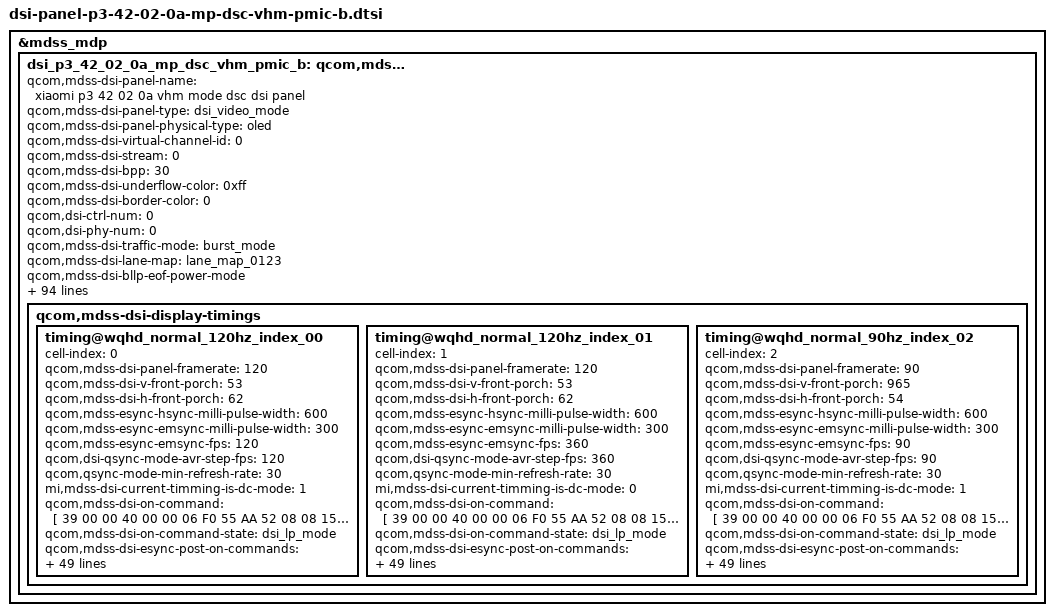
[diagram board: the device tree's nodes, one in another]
&mdss_mdp {
	dsi_p3_42_02_0a_mp_dsc_vhm_pmic_b: qcom,mdss_dsi_p3_42_02_0a_mp_dsc_vhm_pmic_b {
		qcom,mdss-dsi-panel-name = "xiaomi p3 42 02 0a vhm mode dsc dsi panel";
		qcom,mdss-dsi-panel-type = "dsi_video_mode";
		qcom,mdss-dsi-panel-physical-type = "oled";
		qcom,mdss-dsi-virtual-channel-id = <0>;
		qcom,mdss-dsi-stream = <0>;
		qcom,mdss-dsi-bpp = <30>;

		qcom,mdss-dsi-underflow-color = <0xff>;
		qcom,mdss-dsi-border-color = <0>;
		qcom,dsi-ctrl-num = <0>;
		qcom,dsi-phy-num = <0>;
		qcom,mdss-dsi-traffic-mode = "burst_mode";
		qcom,mdss-dsi-lane-map = "lane_map_0123";
		qcom,mdss-dsi-bllp-eof-power-mode;
		qcom,mdss-dsi-bllp-power-mode;
		qcom,mdss-dsi-lane-0-state;
		qcom,mdss-dsi-lane-1-state;
		qcom,mdss-dsi-lane-2-state;
		qcom,mdss-dsi-lane-3-state;
		qcom,mdss-dsi-color-order = "rgb_swap_rgb";
		qcom,mdss-dsi-dma-trigger = "trigger_sw";
		qcom,mdss-dsi-mdp-trigger = "none";
		qcom,mdss-dsi-reset-sequence =<1 1>, <0 1>, <1 10>;
		qcom,mdss-pan-physical-width-dimension = <673>;
		qcom,mdss-pan-physical-height-dimension = <1466>;
		qcom,mdss-dsi-te-pin-select = <1>;
		qcom,mdss-dsi-wr-mem-start = <0x2c>;
		qcom,mdss-dsi-wr-mem-continue = <0x3c>;
		//qcom,mdss-dsi-te-dcs-command = <1>;
		//qcom,mdss-dsi-te-check-enable;
		//qcom,mdss-dsi-te-using-te-pin;
		qcom,mdss-dsi-tx-eot-append;
		qcom,mdss-dsi-lp11-init;
		qcom,mdss-dsi-bl-inverted-dbv;
		qcom,mdss-dsi-panel-dimming-enabled;
		qcom,bl-update-flag = "delay_until_first_frame";
		qcom,mdss-dsi-panel-hdr-enabled;
		qcom,mdss-dsi-panel-hdr-color-primaries = <14500 15500 32000
			17000 15500 30000 8000 3000>;
		qcom,mdss-dsi-panel-peak-brightness = <32000000>;
		qcom,mdss-dsi-panel-blackness-level = <3230>;
		//qcom,mdss-dsi-dma-schedule-line = <1>;
		//qcom,mdss-dsi-dma-schedule-window = <50>;
		qcom,spr-pack-type = "pentile";
		/*
		 * ###############################################################
		 * # Pentile SPR phases for SM8850 and later
		 * ###############################################################
		 * # RG/BG Type A    BG/RG Type A    GR/GB Type A    GB/GR Type A
		 * # R B R B ...     B R B R ...      R B R B ...     B R B R ...
		 * #  G G G G ...     G G G G ...    G G G G ...     G G G G ...
		 * #
		 * # RG/BG Type B    BG/RG Type B    GR/GB Type B    GB/GR Type B
		 * #  G G G G ...     G G G G ...    G G G G ...     G G G G ...
		 * # R B R B ...     B R B R ...      R B R B ...     B R B R ...
		 * ###############################################################
		 */
		qcom,spr-pentile-pack-type = "BG-RG Type A";

		qcom,mdss-disable-cesta-hw-sleep;

		qcom,mdss-dsi-display-timings {

			timing@wqhd_normal_120hz_index_00 {
				#include "dsi-panel-p3-42-02-0a-mp-dsc-vhm-pmic-b-common.dtsi"

				cell-index = <0>;
				qcom,mdss-dsi-panel-framerate = <120>;
				qcom,mdss-dsi-v-front-porch = <53>;
				qcom,mdss-dsi-h-front-porch = <62>;

				qcom,mdss-esync-hsync-milli-pulse-width = <600>;
				qcom,mdss-esync-emsync-milli-pulse-width = <300>;
				qcom,mdss-esync-emsync-fps = <120>;
				qcom,dsi-qsync-mode-avr-step-fps = <120>;
				qcom,qsync-mode-min-refresh-rate = <30>;

				mi,mdss-dsi-current-timming-is-dc-mode = <1>;

				qcom,mdss-dsi-on-command = [
					// LCTC ON
					39 00 00 40 00 00 06 F0 55 AA 52 08 08
					15 00 00 40 00 00 02 BF 21
					// ACTC ON
					15 00 00 40 00 00 02 6F B7
					15 00 00 00 00 00 02 BF 11
					// Power Domain
					39 00 00 40 00 00 06 F0 55 AA 52 08 01
					15 00 00 40 00 00 02 6F 49
					39 00 00 00 00 00 06 B9 01 22 00 EE EE
					// AOD pump
					39 00 00 40 00 00 06 F0 55 AA 52 08 01
					39 00 00 00 00 00 05 B2 00 00 FF 03
					// Data chopper setting
					39 00 00 40 00 00 06 F0 55 AA 52 08 01
					15 00 00 40 00 00 02 6F 23
					39 00 00 00 00 00 04 D9 CB 49 13
					// EM TH2 Duty Setting
					39 00 00 40 00 00 06 F0 55 AA 52 08 00
					39 00 00 40 00 00 02 6F 21
					39 00 00 40 00 00 09 B2 00 28 00 28 00 3C 00 28
					39 00 00 40 00 00 02 6F 75
					39 00 00 40 00 00 09 B2 00 28 00 28 00 3C 00 28
					39 00 00 40 00 00 02 6F 71
					39 00 00 00 00 00 03 B2 00 28
					// PMIC Fast discharge
 					39 00 00 40 00 00 02 6F 51
 					39 00 00 40 00 00 02 D5 02
 					39 00 00 40 00 00 02 6F 54
 					39 00 00 00 00 00 02 D5 1F
 					// Switch VGMP by Fcon
 					39 00 00 40 00 00 06 F0 55 AA 52 08 01
 					39 00 00 40 00 00 02 6F 16
 					39 00 00 00 00 00 05 C6 87 22 2C 2C
 					// demura,FLASH CODE
					39 00 00 40 00 00 06 F0 55 AA 52 08 00
					39 00 00 40 00 00 02 C7 44
					39 00 00 40 00 00 02 6F 31
					39 00 00 40 00 00 03 C0 00 20
					39 00 00 40 00 00 02 6F 06
					39 00 00 40 00 00 03 C7 60 60
					39 00 00 40 00 00 02 6F 08
					39 00 00 40 00 00 03 C7 66 26
					39 00 00 40 00 00 06 F0 55 AA 52 08 04
					39 00 00 00 00 00 02 C0 20
 					// SVM
 					39 00 00 40 00 00 06 F0 55 AA 52 08 00
 					39 00 00 40 00 00 02 6F 20
 					39 00 00 40 00 00 02 B2 03
 					39 00 00 40 00 00 06 F0 55 AA 52 08 01
 					39 00 00 40 00 00 02 6F F0
 					39 00 00 40 00 00 02 C0 F1
 					39 00 00 40 00 00 02 6F F1
 					39 00 00 40 00 00 03 C0 12 12
 					39 00 00 40 00 00 02 6F F4
  					39 00 00 40 00 00 03 C0 12 12
  					39 00 00 40 00 00 02 6F 01
  					39 00 00 40 00 00 04 CE 00 00 00
  					39 00 00 40 00 00 02 6F 94
  					39 00 00 40 00 00 04 E2 00 11 00
  					39 00 00 40 00 00 02 6F 24
  					39 00 00 40 00 00 13 E5 42 8C 94 90 92 07 42 8C 94 90 92 07 42 8C 94 90 92 07
  					39 00 00 40 00 00 02 6F A7
  					39 00 00 40 00 00 02 E7 C0
  					39 00 00 40 00 00 02 6F DA
 					39 00 00 40 00 00 03 E7 00 00
 					39 00 00 40 00 00 06 F0 55 AA 52 08 01
 					39 00 00 40 00 00 02 6F E3
 					39 00 00 00 00 00 18 E5 FF FF FF FF 9B 9B 61 61 4D 4D 3A 3A 00 00 00 00 00 00 00 00 00 00 00
 					// APL,Normal 32,HBM 8,APL 0
 					39 00 00 40 00 00 06 F0 55 AA 52 08 00
 					39 00 00 40 00 00 02 6F 78
 					39 00 00 40 00 00 18 B0 11 00 2A 00 C2 01 DA 03 7C 05 B1 08 80 0B EE 0F FF 05 55 05 56 05 55
 					39 00 00 40 00 00 02 6F 6F
 					39 00 00 40 00 00 07 B0 02 62 04 C4 02 62
 					39 00 00 40 00 00 06 F0 55 AA 52 08 08
 					39 00 00 40 00 00 17 C1 9C FF CC FF FF CC FF FF CC FF FF DC FF FF DD FF FF FF 7F FF 0E FF
 					39 00 00 40 00 00 02 6F 1D
 					39 00 00 40 00 00 07 C1 00 FF FF 4F 00 FF
 					39 00 00 40 00 00 02 6F 23
 					39 00 00 40 00 00 15 C1 0C FF CC FF FF CC FF FF CC FF FF DC FF FF DD FF FF CF 7F 67
 					39 00 00 40 00 00 02 6F 37
 					39 00 00 40 00 00 15 C1 0C FF CC FF FF CC FF FF CC FF FF DC FF FF DD FF FF FF 7F FF
 					39 00 00 40 00 00 02 6F 4B
 					39 00 00 00 00 00 15 C1 0C FF CC FF FF CC FF FF CC FF FF DC FF FF DD FF FF CF 7F 67
  					// Data Scaling DBV_TH
  					39 00 00 00 00 00 2D BA 00 07 00 26 00 26 00 64 00 64 00 AC 00 AC 01 26 01 26 02 5F 02 5F 02 60 02 60 07 FB 07 FB 17 FE 17 FE 1F FF 1F FF 34 BC 34 BC 3F FE
					// ESD ERR Flag
					39 00 00 40 00 00 06 F0 55 AA 52 08 00
					39 00 00 40 00 00 03 BE 47 45
					15 00 00 40 00 00 02 6F 05
					15 00 00 40 00 00 02 BE 00
					15 00 00 40 00 00 02 6F 19
					39 00 00 00 00 00 05 BE 10 0A 00 9C
					// DVDD Low Voltage detect
					39 00 00 40 00 00 06 F0 55 AA 52 08 01
					15 00 00 40 00 00 02 6F 03
					15 00 00 00 00 00 02 C7 C7
  					// ESD protect
  					39 00 00 40 00 00 05 FF AA 55 A5 81
  					39 00 00 40 00 00 02 6F 0F
  					39 00 00 00 00 00 02 FD 80
  					// 1220*2656
  					39 00 00 40 00 00 05 2A 00 00 04 C3
  					39 00 00 00 00 00 05 2B 00 00 0A 5F
  					// VESA Setting
 					39 00 00 40 00 00 02 90 03
 					39 00 00 40 00 00 02 6F 01
 					39 00 00 40 00 00 02 90 43
 					39 00 00 40 00 00 13 91 89 28 00 10 C2 00 02 32 01 9C 00 08 06 67 05 92 10 E0
 					// DC 120Hz
 					39 00 00 40 00 00 02 2F 30
 					39 00 00 00 00 00 02 6D 00
 					// TE On
 					39 00 00 00 00 00 02 35 00
 					// DBV = 0
					39 00 00 00 00 00 03 51 00 00
					// idle_dimming_dbv = 0
					39 00 00 40 00 00 02 6F 04
					39 00 00 00 00 00 03 51 00 00
					// BCTRL = 1, DD = 0
					39 00 00 00 00 00 02 53 20
					// 0x00 Data remap off 0x0F Data remap on
					39 00 00 40 00 00 06 F0 55 AA 52 08 00
					39 00 00 40 00 00 02 6F 02
					39 00 00 40 00 00 02 B2 0F
 					// Skip mode setting
					39 00 00 40 00 00 04 8C 00 00 10
					39 00 00 40 00 00 03 5A 00 00
					39 00 00 00 00 00 02 2F 30
					// AP SPR
					39 00 00 40 00 00 06 F0 55 AA 52 08 03
					39 00 00 40 00 00 02 6F 09
					39 00 00 40 00 00 07 DE 10 34 25 30 14 25
					39 00 00 40 00 00 06 F0 55 AA 52 08 07
					39 00 00 40 00 00 06 B0 84 44 00 00 40
					39 00 00 40 00 00 07 B1 18 08 00 08 18 00
					39 00 00 00 00 00 13 91 AB F0 00 10 C1 00 01 CB 00 73 00 33 06 67 1F B0 11 40
					// Still = 0 VDO no RAM
					39 00 00 00 00 00 02 18 00
					// GPO2 = Vsync
					39 00 00 40 00 00 06 F0 55 AA 52 08 00
					39 00 00 40 00 00 02 6F 02
 					39 00 00 40 00 00 03 BE 4F 4A
 					39 00 00 40 00 00 02 6F 0A
 					39 00 00 00 00 00 02 BE 02
 					// VDO with RAM
 					39 00 00 40 00 00 06 F0 55 AA 52 08 01
 					39 00 00 40 00 00 02 6F 17
 					39 00 00 00 00 00 02 B8 07
 					// GMA By Frame
 					39 00 00 40 00 00 06 F0 55 AA 52 08 02
 					39 00 00 00 00 00 02 CC 10
					// Idle Mode porch
					39 00 00 40 00 00 05 FF AA 55 A5 81
					39 00 00 40 00 00 02 6F 0F
					39 00 00 00 00 00 02 F5 0E
					// Demura on
					39 00 00 40 00 00 06 F0 55 AA 52 08 04
					39 00 00 00 00 00 02 CA 01
					// A3 Setting
					39 00 00 40 00 00 06 F0 55 AA 52 08 04
					39 00 00 40 00 00 02 6F 06
					39 00 00 40 00 00 02 B5 00
					39 00 00 40 00 00 05 FF AA 55 A5 81
					39 00 00 40 00 00 02 6F 0D
					39 00 00 40 00 00 02 FD 40
					39 00 00 40 00 00 07 51 00 00 00 00 00 00
					39 00 00 00 00 00 06 A3 84 02 5F 02 5F
					// osc trace
					39 00 00 40 00 00 06 F0 55 AA 52 08 01
					39 00 00 40 00 00 37 C3 00 00 00 00 EA 00 00 00 00 EA 00 00 00 00 00 00 00 00 00 00 00 00 00 00 00 00 00 00 00 00 00 00 00 00 00 00 00 00 00 00 00 00 00 00 00 00 00 11 00 AA 02 AA 02 00
					39 00 00 00 00 00 24 EA 11 02 3C 00 0D 0B 0A 01 7C 00 00 11 02 3C 00 0D 0B 0A 01 A7 00 00 00 00 00 00 01 7C 01 A7 00 0C 00 00 40
					//vdo drop=1.1s
					39 00 00 40 00 00 06 F0 55 AA 52 08 03
					15 00 00 40 00 00 02 6F 1D
					15 00 00 40 00 00 02 C6 0C
					//0xB4AA=4583  46250*8*3=1.1S
					15 00 00 40 00 00 02 6F 2C
					39 00 00 00 00 00 07 C6 AA B4 AA B4 AA B4
					// Sleep Out
					05 00 00 00 78 00 01 11
					// expand demura lut 16DBV*7Gray
					39 00 00 40 00 00 13 A3 84 02 5F 02 5F 02 04 B5 02 03 00 03 00 00 00 00 00 00
					39 00 00 40 00 00 02 6F 12
					39 00 00 40 00 00 0E A3 01 00 9D 00 00 AA 00 00 00 00 00 00 00
					39 00 00 40 00 00 02 6F 53
					39 00 00 40 00 00 0E A3 02 04 B5 02 03 00 0C 00 00 00 00 00 00
					39 00 00 40 00 00 02 6F 60
					39 00 00 00 00 00 0E A3 01 00 9D 00 00 AA 00 00 00 00 00 00 00

					// Display On
					05 00 00 00 00 00 01 29
					// ESD ERR Flag on
					39 00 00 40 00 00 06 F0 55 AA 52 08 00
					15 00 00 40 00 00 02 6F 05
					15 00 00 00 00 00 02 BE 08

					// VHM Setting
					// opt_level2_te_fall=1,Level TE drop position reference multi-TE
					39 01 00 40 00 00 04 8D 00 20 00
					15 01 00 40 00 00 02 6F 8A
					15 01 00 40 00 00 02 44 19
					39 01 00 40 00 00 06 F0 55 AA 52 08 00
					39 01 00 40 00 00 03 BE 47 45
					// Level_TE(0x6A)、ARP(0x77)、Test_TE(0x7D)
					15 01 00 40 00 00 02 6F 14
					39 01 00 40 00 00 04 35 6A 77 E0
					15 01 00 40 00 00 02 6F 17
					39 01 00 40 00 00 04 35 6A 77 E0
					15 01 00 40 00 00 02 6F 1A
					39 01 00 40 00 00 04 35 6A 77 E0
					15 01 00 40 00 00 02 6F 1D
					39 01 00 40 00 00 04 35 6A 77 E0
					// dyn_multi_te_start[13:0]adjust TE left
					15 01 00 40 00 00 02 6F 26
					39 01 00 40 00 00 03 44 00 78
					// dyn_multi_te_start_skip[13:0]adjust TE left
					15 01 00 40 00 00 02 6F 28
					39 01 00 40 00 00 03 44 00 78
					// dyn_multi_te_start_video[13:0]adjust TE left
					15 01 00 40 00 00 02 6F 42
					39 01 00 40 00 00 03 44 00 78
					// dyn_multi_te_start_vdo_skip[13:0]adjust TE left
					15 01 00 40 00 00 02 6F 64
					39 01 00 40 00 00 03 44 00 78
					// dyn_multi_te_width[7:0]
					15 01 00 40 00 00 02 6F 2A
					15 01 00 40 00 00 02 44 1A
					// dyn_multi_te_interval[13:0]=2736
					15 01 00 40 00 00 02 6F 2B
					39 01 00 40 00 00 03 44 0A B0
					// TE07_DPU_DELAY[7:0]
					15 01 00 40 00 00 02 6F 02
					15 01 00 40 00 00 02 35 18
					// SEL_ECK_CYCLE_LINE=0,EXTEND_VFP_LINE_ECLK_EN=0
					39 01 00 40 00 00 06 F0 55 AA 52 08 00
					15 01 00 40 00 00 02 6F 04
					15 01 00 40 00 00 02 BA 00
					// TE07_DPU_DELAY_VDO[7:0]
					15 01 00 40 00 00 02 6F 0C
					15 01 00 40 00 00 02 35 00
					// set_dsi_mode=1
					15 01 00 40 00 00 02 71 01
					// still=1
					15 01 00 40 00 00 02 18 00
					// REGW 0x6D,0x04
					// EXT_HSYNC_EN=1
					39 01 00 40 00 00 06 F0 55 AA 52 08 03
					15 01 00 40 00 00 02 6F 06
					15 01 00 40 00 00 02 BA 01
					// DFC_mode3
					39 01 00 40 00 00 04 2F 30 05 30
					// ARP_TE selects TE1F
					39 01 00 40 00 00 06 F0 55 AA 52 08 00
					15 01 00 40 00 00 02 6F 35
					15 01 00 40 00 00 02 B1 10
					39 01 00 40 00 00 06 F0 55 AA 52 08 00
					// opt_dis_vdo_ltpo_crc=1(Disable CRC calculation), 0 (default: calculate CRC)
					15 01 00 40 00 00 02 6F DD
					15 01 00 40 00 00 02 BA 80
					// FD fixedly retreats one line
					39 01 00 40 00 00 06 F0 55 AA 52 08 08
					15 01 00 40 00 00 02 6F 02
					15 01 00 40 00 00 02 E0 81
					// 20250514
					// opt_v2c_chg_reload_fskip=1:Set skip frame_skip to return EM to sequence 1 without skipping the sequence
					// opt_v2c_chg_reload_fskip=0:Jump out of sequence
					// opt_level2_te_fall=1(707A only) _wrote about deletion before
					// REGW 0x6F,0x8A
					// REGW 0x44,0x11
					// 20BAE2[3]=1，V2C receives the outbound VSS and requests sequence 1 back (this question assumes that the V2C VSS follows the TE and does not generate an ARP, which would allow the VSS to match the TE's response)
					39 01 00 40 00 00 06 F0 55 AA 52 08 00
					15 01 00 40 00 00 02 6F E2
					15 01 00 40 00 00 02 BA 08
					// 31FB00[4]=1，By default, the frame sent to V2C will not use extd_vfp. When vcnt_val_clr is seen, v is generated. Setting opt_rgb_v_gate_afp=1 will make the V2C frame also use extd_vfp
					39 01 00 40 00 00 05 FF AA 55 A5 81
					15 01 00 40 00 00 02 6F 00
					15 01 00 40 00 00 02 FB 10
					// CMD3,Page1
					// Enable the VESA CLK function to stop CLK in the skip frame. VESA CLK will still be enabled by MIPI writing
					39 01 00 40 00 00 05 FF AA 55 A5 81
					15 01 00 40 00 00 02 6F 1C
					15 01 00 40 00 00 02 FB 10
					// 707A_P3_Y=2736，Xiaomi P3_VHM, still=1, using TE2 to achieve ALS 60Hz
					// TE_RW_rising_command mode
					// dyn_multi_te_start=dyn_multi_te_start_skip=0x1A/ =dyn_multi_te_width=0x1A/dyn_multi_te_interval=0x1560
					15 01 00 40 00 00 02 6F 2D
					39 01 00 40 00 00 08 44 00 1A 00 1A 1A 15 60
					// dyn_multi_te_start=dyn_multi_te_start_skip=0x1A/ =dyn_multi_te_width=0x1A/dyn_multi_te_interval=0x1560
					15 01 00 40 00 00 02 6F 3B
					39 01 00 40 00 00 08 44 00 1A 00 1A 1A 15 60
					// 707A
					15 01 00 40 00 00 02 6F 69
					15 01 00 00 00 00 02 44 02
					// TE20_sel_cmd=7D(Test TE)
					// REGW 0x6F,0x16
					// REGW 0x35,0xE0
					// REGW 0x6F,0x19
					// REGW 0x35,0xE0
					// REGW 0x6F,0x1C
					// REGW 0x35,0xE0
					// REGW 0x6F,0x1F
					// REGW 0x35,0xE0
					//VHM setting,DC write common after 6D
					//DC
					15 01 00 40 00 00 02 6F 2B
					39 01 00 40 00 00 03 44 0A B0
					//DC 1HZ
					39 01 00 40 00 00 06 F0 55 AA 52 08 00
					15 01 00 40 00 00 02 6F 0E
					15 01 00 40 00 00 02 C0 00
					15 01 00 40 00 00 02 6F DE
					15 01 00 40 00 00 02 BA 00
					15 01 00 40 00 00 02 6F 04
					15 01 00 40 00 00 02 35 01
					15 01 00 40 00 00 02 6F 14
					15 01 00 40 00 00 02 35 6A
					39 01 00 40 00 00 03 44 0A 60
					15 01 00 40 00 00 02 8C 02
					15 01 00 40 00 00 02 6D 0B
					//VHM setting,DC write common after 6D
					//120Hz DC Skip Frame Rate
					39 01 00 40 00 00 06 F0 55 AA 52 08 00
					15 01 00 40 00 00 02 6F B8
					39 01 00 40 00 00 09 BA 10 10 00 00 00 01 20 21
					15 01 00 40 00 00 02 6F C0
					39 01 00 40 00 00 09 BA 10 10 00 00 00 01 20 21
					15 01 00 40 00 00 02 6F 5A
					39 01 00 40 00 00 09 D1 10 10 00 00 00 01 20 21
					15 01 00 40 00 00 02 6F 31
					15 01 00 40 00 00 02 C0 00
					39 01 00 40 00 00 2C A9 01 00 2F 00 00 30 02 01 B9 2C 2C 21 02 01 B9 30 30 F0 01 00 A2 00 14 05 02 01 B9 2C 2C 22 00 00 00 00 00 00 00 02 01 B9 30 30 26
					39 01 00 40 00 00 13 A3 84 02 5F 02 5F 02 04 B5 02 03 00 03 00 00 00 00 00 00
					15 01 00 40 00 00 02 6F 12
					39 01 00 40 00 00 0E A3 01 00 9D 00 00 AA 00 00 00 00 00 00 00
					15 01 00 40 00 00 02 6F 53
					39 01 00 40 00 00 0E A3 02 04 B5 02 03 00 0C 00 00 00 00 00 00
					15 01 00 40 00 00 02 6F 60
					39 01 00 40 00 00 0E A3 01 00 9D 00 00 AA 00 00 00 00 00 00 00
					//DC mode 120 DC/90 DC/skip frame rate
					39 01 00 40 00 00 06 F0 55 AA 52 08 08
					39 01 00 40 00 00 11 B6 09 D7 09 D7 09 D7 09 D7 09 D7 09 D7 09 D7 09 D7
					15 01 00 40 00 00 02 6F 10
					39 01 00 40 00 00 11 B6 09 D7 09 D7 09 D7 09 D7 0E 27 0E 27 0E 27 0E 27
					15 01 00 40 00 00 02 6F 20
					39 01 00 40 00 00 0F B6 0E 27 0E 27 0E 27 0E 27 0F FF 0F FF 0F FF
					39 01 00 40 00 00 11 B7 00 00 00 00 00 00 00 00 00 00 00 00 00 00 00 00
					15 01 00 40 00 00 02 6F 10
					39 01 00 40 00 00 11 B7 00 00 00 00 08 00 08 00 08 00 08 00 08 00 08 00
					15 01 00 40 00 00 02 6F 20
					39 01 00 40 00 00 0F B7 07 78 07 78 07 78 07 78 07 78 07 78 08 00
					//120hz DC mode
					39 01 00 40 00 00 06 F0 55 AA 52 08 01
					15 01 00 40 00 00 02 6F 0E
					39 01 00 40 00 00 05 B8 D8 87 D8 88
					39 01 00 40 00 00 06 F0 55 AA 52 08 05
					15 01 00 40 00 00 02 6F 03
					15 01 00 40 00 00 02 E1 02
					//od DC
					39 01 00 40 00 00 06 F0 55 AA 52 08 08
					15 01 00 40 00 00 02 6F 0E
					39 01 00 40 00 00 0F E1 01 02 03 04 04 04 04 04 06 08 0D 0F 13 18
					39 01 00 40 00 00 0F E2 0C 18 20 36 33 30 30 35 2A 25 20 1A 10 09
					15 01 00 40 00 00 02 6F 0E
					39 01 00 40 00 00 0F E2 06 0C 11 2A 2A 2A 2A 20 1A 15 10 0F 0A 09
					15 01 00 40 00 00 02 6F 1C
					39 01 00 40 00 00 0F E2 06 0C 11 12 12 13 17 17 13 10 0D 0B 09 08
					15 01 00 40 00 00 02 6F 2A
					39 01 00 40 00 00 0F E2 03 06 0A 0D 0C 0B 0D 0D 0C 0A 09 09 08 07
					15 01 00 40 00 00 02 6F 38
					39 01 00 40 00 00 0F E2 02 04 06 08 07 08 09 09 0A 09 0A 09 08 07
					15 01 00 40 00 00 02 6F 46
					39 01 00 40 00 00 0F E2 01 02 03 05 04 06 04 04 07 09 0C 0F 11 16
					15 01 00 40 00 00 02 6F 54
					39 01 00 40 00 00 0F E2 01 02 03 05 04 06 05 05 07 0A 0C 0F 12 17
					15 01 00 40 00 00 02 6F 62
					39 01 00 40 00 00 0F E2 01 02 02 03 04 05 04 04 07 0A 0D 10 11 16
					15 01 00 40 00 00 02 6F 1B
					39 01 00 40 00 00 07 EB 34 E0 00 05 00 00
					// reload demura
					39 01 00 40 00 00 06 F0 55 AA 52 08 04
					15 01 00 40 00 00 02 6F 02
					39 01 00 40 00 00 03 B5 00 03
					15 01 00 00 00 00 02 9D AA
				];
				qcom,mdss-dsi-on-command-state = "dsi_lp_mode";

				qcom,mdss-dsi-esync-post-on-commands = [
					39 01 00 40 00 00 06 F0 55 AA 52 08 03
					39 01 00 40 00 00 02 6F 06
					// 00 -> MIPI Hsync  01 -> Ext Hsync
					39 01 00 00 00 00 02 BA 01
				];
				qcom,mdss-dsi-esync-post-on-commands-state = "dsi_hs_mode";

				qcom,mdss-dsi-qsync-freq-step-sequence-interval =
					<0 120000 1>, <0 60000 1>, <1 120000 1>, <1 60000 1>;
				qcom,mdss-dsi-qsync-freq-step-sequence  =
					<30000 1>,
					<30000 1>,
					<30000 1>,
					<30000 1>;

				qcom,mdss-dsi-sticky_still_en-command = [
					39 01 00 00 00 00 1A A9 01 00 18 00 00 01 02 00 D1 6E 6F 3F F0 02 00 BE 02 02 60 01 00 44 69 69 02
				];
				qcom,mdss-dsi-sticky_still_disable-command = [
					39 01 00 00 00 00 1A A9 01 00 18 00 00 00 02 00 D1 6E 6F FF FF 02 00 BE 02 02 47 01 00 44 69 69 00
				];
				qcom,mdss-dsi-sticky_still_en-command-state = "dsi_lp_mode";
				qcom,mdss-dsi-sticky_still_disable-command-state = "dsi_lp_mode";

				qcom,mdss-dsi-qsync-freq-pattren-needs-selfrefresh =
					<1 1 1 1>;

				qcom,mdss-dsi-freq-step-pattern1-command = [
					// Non Cmd Setting
					39 01 00 00 00 00 06 F0 55 AA 52 08 00
				];
				qcom,mdss-dsi-freq-step-pattern1-command-state = "dsi_lp_mode";

				qcom,mdss-dsi-freq-step-pattern2-command = [
					// Non Cmd Setting
					39 01 00 00 00 00 06 F0 55 AA 52 08 00
				];
				qcom,mdss-dsi-freq-step-pattern2-command-state = "dsi_lp_mode";

				qcom,mdss-dsi-freq-step-pattern3-command = [
					// Non Cmd Setting
					39 01 00 00 00 00 06 F0 55 AA 52 08 00
				];
				qcom,mdss-dsi-freq-step-pattern3-command-state = "dsi_lp_mode";

				qcom,mdss-dsi-freq-step-pattern4-command = [
					// Non Cmd Setting
					39 01 00 00 00 00 06 F0 55 AA 52 08 00
				];
				qcom,mdss-dsi-freq-step-pattern4-command-state = "dsi_lp_mode";

				qcom,mdss-dsi-em-pulse-switch-command = [
					//VHM setting,DC write common after 6D
					//DC
					15 01 00 40 00 00 02 6F 2B
					39 01 00 40 00 00 03 44 0A B0
					//DC 1HZ
					39 01 00 40 00 00 06 F0 55 AA 52 08 00
					15 01 00 40 00 00 02 6F 0E
					15 01 00 40 00 00 02 C0 00
					15 01 00 40 00 00 02 6F DE
					15 01 00 40 00 00 02 BA 00
					15 01 00 40 00 00 02 6F 04
					15 01 00 40 00 00 02 35 01
					15 01 00 40 00 00 02 6F 14
					15 01 00 40 00 00 02 35 6A
					39 01 00 40 00 00 03 44 0A 60
					15 01 00 40 00 00 02 8C 02
					15 01 00 40 00 00 02 6D 0B
					//VHM setting,DC write common after 6D
					//707A_P3_Y=2736，Xiaomi P3_VHM, still=1, using TE2 to achieve ALS 90Hz
					//TE_RW_rising_command mode
					//dyn_multi_te_start=dyn_multi_te_start_skip=0x1A/ =dyn_multi_te_width=0x1A/dyn_multi_te_interval=0x1008
					15 01 00 40 00 00 02 6F 2D
					39 01 00 40 00 00 08 44 00 1A 00 1A 1A 15 60
					//dyn_multi_te_start=dyn_multi_te_start_skip=0x1A/ =dyn_multi_te_width=0x1A/dyn_multi_te_interval=0x1008
					15 01 00 40 00 00 02 6F 3B
					39 01 00 00 00 00 08 44 00 1A 00 1A 1A 15 60
				];
				qcom,mdss-dsi-em-pulse-switch-command-state = "dsi_hs_mode";

				mi,mdss-dsi-em-pulse-supplement-switch-command = [
					//VHM setting,DC write common after 6D
					//DC
					15 01 00 40 00 00 02 6F 2B
					39 01 00 40 00 00 03 44 0A B0
					//DC 1HZ
					39 01 00 40 00 00 06 F0 55 AA 52 08 00
					15 01 00 40 00 00 02 6F 0E
					15 01 00 40 00 00 02 C0 00
					15 01 00 40 00 00 02 6F DE
					15 01 00 40 00 00 02 BA 00
					15 01 00 40 00 00 02 6F 04
					15 01 00 40 00 00 02 35 01
					15 01 00 40 00 00 02 6F 14
					15 01 00 40 00 00 02 35 6A
					39 01 00 40 00 00 03 44 0A 60
					15 01 00 40 00 00 02 8C 02
					15 01 00 40 00 00 02 6D 0B
					//VHM setting,DC write common after 6D
					//707A_P3_Y=2736，Xiaomi P3_VHM, still=1, using TE2 to achieve ALS 90Hz
					//TE_RW_rising_command mode
					//dyn_multi_te_start=dyn_multi_te_start_skip=0x1A/ =dyn_multi_te_width=0x1A/dyn_multi_te_interval=0x1008
					15 01 00 40 00 00 02 6F 2D
					39 01 00 40 00 00 08 44 00 1A 00 1A 1A 15 60
					//dyn_multi_te_start=dyn_multi_te_start_skip=0x1A/ =dyn_multi_te_width=0x1A/dyn_multi_te_interval=0x1008
					15 01 00 40 00 00 02 6F 3B
					39 01 00 40 00 00 08 44 00 1A 00 1A 1A 15 60
					//120Hz DC Skip Frame Rate
					39 01 00 40 00 00 06 F0 55 AA 52 08 00
					15 01 00 40 00 00 02 6F B8
					39 01 00 40 00 00 09 BA 10 10 00 00 00 01 20 21
					15 01 00 40 00 00 02 6F C0
					39 01 00 40 00 00 09 BA 10 10 00 00 00 01 20 21
					15 01 00 40 00 00 02 6F 5A
					39 01 00 40 00 00 09 D1 10 10 00 00 00 01 20 21
					15 01 00 40 00 00 02 6F 31
					15 01 00 40 00 00 02 C0 00
					39 01 00 40 00 00 2C A9 01 00 2F 00 00 30 02 01 B9 2C 2C 21 02 01 B9 30 30 F0 01 00 A2 00 14 05 02 01 B9 2C 2C 22 00 00 00 00 00 00 00 02 01 B9 30 30 26
					39 01 00 40 00 00 13 A3 84 02 5F 02 5F 02 04 B5 02 03 00 03 00 00 00 00 00 00
					15 01 00 40 00 00 02 6F 12
					39 01 00 40 00 00 0E A3 01 00 9D 00 00 AA 00 00 00 00 00 00 00
					15 01 00 40 00 00 02 6F 53
					39 01 00 40 00 00 0E A3 02 04 B5 02 03 00 0C 00 00 00 00 00 00
					15 01 00 40 00 00 02 6F 60
					39 01 00 40 00 00 0E A3 01 00 9D 00 00 AA 00 00 00 00 00 00 00
					//	DC mode 120 DC/90 DC/skip frame rate
					39 01 00 40 00 00 06 F0 55 AA 52 08 08
					39 01 00 40 00 00 11 B6 09 D7 09 D7 09 D7 09 D7 09 D7 09 D7 09 D7 09 D7
					15 01 00 40 00 00 02 6F 10
					39 01 00 40 00 00 11 B6 09 D7 09 D7 09 D7 09 D7 0E 27 0E 27 0E 27 0E 27
					15 01 00 40 00 00 02 6F 20
					39 01 00 40 00 00 0F B6 0E 27 0E 27 0E 27 0E 27 0F FF 0F FF 0F FF
					39 01 00 40 00 00 11 B7 00 00 00 00 00 00 00 00 00 00 00 00 00 00 00 00
					15 01 00 40 00 00 02 6F 10
					39 01 00 40 00 00 11 B7 00 00 00 00 08 00 08 00 08 00 08 00 08 00 08 00
					15 01 00 40 00 00 02 6F 20
					39 01 00 40 00 00 0F B7 07 78 07 78 07 78 07 78 07 78 07 78 08 00
					//120hz DC mode
					39 01 00 40 00 00 06 F0 55 AA 52 08 01
					15 01 00 40 00 00 02 6F 0E
					39 01 00 40 00 00 05 B8 D8 87 D8 88
					39 01 00 40 00 00 06 F0 55 AA 52 08 05
					15 01 00 40 00 00 02 6F 03
					15 01 00 40 00 00 02 E1 02
					//od DC
					39 01 00 40 00 00 06 F0 55 AA 52 08 08
					15 01 00 40 00 00 02 6F 0E
					39 01 00 40 00 00 0F E1 01 02 03 04 04 04 04 04 06 08 0D 0F 13 18
					39 01 00 40 00 00 0F E2 0C 18 20 36 33 30 30 35 2A 25 20 1A 10 09
					15 01 00 40 00 00 02 6F 0E
					39 01 00 40 00 00 0F E2 06 0C 11 2A 2A 2A 2A 20 1A 15 10 0F 0A 09
					15 01 00 40 00 00 02 6F 1C
					39 01 00 40 00 00 0F E2 06 0C 11 12 12 13 17 17 13 10 0D 0B 09 08
					15 01 00 40 00 00 02 6F 2A
					39 01 00 40 00 00 0F E2 03 06 0A 0D 0C 0B 0D 0D 0C 0A 09 09 08 07
					15 01 00 40 00 00 02 6F 38
					39 01 00 40 00 00 0F E2 02 04 06 08 07 08 09 09 0A 09 0A 09 08 07
					15 01 00 40 00 00 02 6F 46
					39 01 00 40 00 00 0F E2 01 02 03 05 04 06 04 04 07 09 0C 0F 11 16
					15 01 00 40 00 00 02 6F 54
					39 01 00 40 00 00 0F E2 01 02 03 05 04 06 05 05 07 0A 0C 0F 12 17
					15 01 00 40 00 00 02 6F 62
					39 01 00 40 00 00 0F E2 01 02 02 03 04 05 04 04 07 0A 0D 10 11 16
					15 01 00 40 00 00 02 6F 1B
					39 01 00 00 00 00 07 EB 34 E0 00 05 00 00
				];
				mi,mdss-dsi-em-pulse-supplement-switch-command-state = "dsi_hs_mode";

				mi,mdss-dsi-demura-over-threshold-command = [
					39 01 00 40 00 00 06 F0 55 AA 52 08 04
					15 01 00 40 00 00 02 6F 02
					39 01 00 40 00 00 03 B5 00 0C
					15 01 00 00 00 00 02 9D AA
				];
				mi,mdss-dsi-demura-over-threshold-command-state = "dsi_hs_mode";

				mi,mdss-dsi-demura-under-threshold-command = [
					39 01 00 40 00 00 06 F0 55 AA 52 08 04
					15 01 00 40 00 00 02 6F 02
					39 01 00 40 00 00 03 B5 00 03
					15 01 00 00 00 00 02 9D AA
				];
				mi,mdss-dsi-demura-under-threshold-command-state = "dsi_hs_mode";
			};

			timing@wqhd_normal_120hz_index_01 {
				#include "dsi-panel-p3-42-02-0a-mp-dsc-vhm-pmic-b-common.dtsi"

				cell-index = <1>;
				qcom,mdss-dsi-panel-framerate = <120>;
				qcom,mdss-dsi-v-front-porch = <53>;
				qcom,mdss-dsi-h-front-porch = <62>;

				qcom,mdss-esync-hsync-milli-pulse-width = <600>;
				qcom,mdss-esync-emsync-milli-pulse-width = <300>;
				qcom,mdss-esync-emsync-fps = <360>;
				qcom,dsi-qsync-mode-avr-step-fps = <360>;
				qcom,qsync-mode-min-refresh-rate = <30>;

				mi,mdss-dsi-current-timming-is-dc-mode = <0>;

				qcom,mdss-dsi-on-command = [
					// LCTC ON
					39 00 00 40 00 00 06 F0 55 AA 52 08 08
					15 00 00 40 00 00 02 BF 21
					// ACTC ON
					15 00 00 40 00 00 02 6F B7
					15 00 00 00 00 00 02 BF 11
					// Power Domain
					39 00 00 40 00 00 06 F0 55 AA 52 08 01
					15 00 00 40 00 00 02 6F 49
					39 00 00 00 00 00 06 B9 01 22 00 EE EE
					// AOD pump
					39 00 00 40 00 00 06 F0 55 AA 52 08 01
					39 00 00 00 00 00 05 B2 00 00 FF 03
					// Data chopper setting
					39 00 00 40 00 00 06 F0 55 AA 52 08 01
					15 00 00 40 00 00 02 6F 23
					39 00 00 00 00 00 04 D9 CB 49 13
					// EM TH2 Duty Setting
					39 00 00 40 00 00 06 F0 55 AA 52 08 00
					39 00 00 40 00 00 02 6F 21
					39 00 00 40 00 00 09 B2 00 28 00 28 00 3C 00 28
					39 00 00 40 00 00 02 6F 75
					39 00 00 40 00 00 09 B2 00 28 00 28 00 3C 00 28
					39 00 00 40 00 00 02 6F 71
					39 00 00 00 00 00 03 B2 00 28
					// PMIC Fast discharge
 					39 00 00 40 00 00 02 6F 51
 					39 00 00 40 00 00 02 D5 02
 					39 00 00 40 00 00 02 6F 54
 					39 00 00 00 00 00 02 D5 1F
 					// Switch VGMP by Fcon
 					39 00 00 40 00 00 06 F0 55 AA 52 08 01
 					39 00 00 40 00 00 02 6F 16
 					39 00 00 00 00 00 05 C6 87 22 2C 2C
 					// demura,FLASH CODE
					39 00 00 40 00 00 06 F0 55 AA 52 08 00
					39 00 00 40 00 00 02 C7 44
					39 00 00 40 00 00 02 6F 31
					39 00 00 40 00 00 03 C0 00 20
					39 00 00 40 00 00 02 6F 06
					39 00 00 40 00 00 03 C7 60 60
					39 00 00 40 00 00 02 6F 08
					39 00 00 40 00 00 03 C7 66 26
					39 00 00 40 00 00 06 F0 55 AA 52 08 04
					39 00 00 00 00 00 02 C0 20
 					// SVM
 					39 00 00 40 00 00 06 F0 55 AA 52 08 00
 					39 00 00 40 00 00 02 6F 20
 					39 00 00 40 00 00 02 B2 03
 					39 00 00 40 00 00 06 F0 55 AA 52 08 01
 					39 00 00 40 00 00 02 6F F0
 					39 00 00 40 00 00 02 C0 F1
 					39 00 00 40 00 00 02 6F F1
 					39 00 00 40 00 00 03 C0 12 12
 					39 00 00 40 00 00 02 6F F4
  					39 00 00 40 00 00 03 C0 12 12
  					39 00 00 40 00 00 02 6F 01
  					39 00 00 40 00 00 04 CE 00 00 00
  					39 00 00 40 00 00 02 6F 94
  					39 00 00 40 00 00 04 E2 00 11 00
  					39 00 00 40 00 00 02 6F 24
  					39 00 00 40 00 00 13 E5 42 8C 94 90 92 07 42 8C 94 90 92 07 42 8C 94 90 92 07
  					39 00 00 40 00 00 02 6F A7
  					39 00 00 40 00 00 02 E7 C0
  					39 00 00 40 00 00 02 6F DA
 					39 00 00 40 00 00 03 E7 00 00
 					39 00 00 40 00 00 06 F0 55 AA 52 08 01
 					39 00 00 40 00 00 02 6F E3
 					39 00 00 00 00 00 18 E5 FF FF FF FF 9B 9B 61 61 4D 4D 3A 3A 00 00 00 00 00 00 00 00 00 00 00
 					// APL,Normal 32,HBM 8,APL 0
 					39 00 00 40 00 00 06 F0 55 AA 52 08 00
 					39 00 00 40 00 00 02 6F 78
 					39 00 00 40 00 00 18 B0 11 00 2A 00 C2 01 DA 03 7C 05 B1 08 80 0B EE 0F FF 05 55 05 56 05 55
 					39 00 00 40 00 00 02 6F 6F
 					39 00 00 40 00 00 07 B0 02 62 04 C4 02 62
 					39 00 00 40 00 00 06 F0 55 AA 52 08 08
 					39 00 00 40 00 00 17 C1 9C FF CC FF FF CC FF FF CC FF FF DC FF FF DD FF FF FF 7F FF 0E FF
 					39 00 00 40 00 00 02 6F 1D
 					39 00 00 40 00 00 07 C1 00 FF FF 4F 00 FF
 					39 00 00 40 00 00 02 6F 23
 					39 00 00 40 00 00 15 C1 0C FF CC FF FF CC FF FF CC FF FF DC FF FF DD FF FF CF 7F 67
 					39 00 00 40 00 00 02 6F 37
 					39 00 00 40 00 00 15 C1 0C FF CC FF FF CC FF FF CC FF FF DC FF FF DD FF FF FF 7F FF
 					39 00 00 40 00 00 02 6F 4B
 					39 00 00 00 00 00 15 C1 0C FF CC FF FF CC FF FF CC FF FF DC FF FF DD FF FF CF 7F 67
  					// Data Scaling DBV_TH
  					39 00 00 00 00 00 2D BA 00 07 00 26 00 26 00 64 00 64 00 AC 00 AC 01 26 01 26 02 5F 02 5F 02 60 02 60 07 FB 07 FB 17 FE 17 FE 1F FF 1F FF 34 BC 34 BC 3F FE
					// ESD ERR Flag
					39 00 00 40 00 00 06 F0 55 AA 52 08 00
					39 00 00 40 00 00 03 BE 47 45
					15 00 00 40 00 00 02 6F 05
					15 00 00 40 00 00 02 BE 00
					15 00 00 40 00 00 02 6F 19
					39 00 00 00 00 00 05 BE 10 0A 00 9C
					// DVDD Low Voltage detect
					39 00 00 40 00 00 06 F0 55 AA 52 08 01
					15 00 00 40 00 00 02 6F 03
					15 00 00 00 00 00 02 C7 C7
  					// ESD protect
  					39 00 00 40 00 00 05 FF AA 55 A5 81
  					39 00 00 40 00 00 02 6F 0F
  					39 00 00 00 00 00 02 FD 80
  					// 1220*2656
  					39 00 00 40 00 00 05 2A 00 00 04 C3
  					39 00 00 00 00 00 05 2B 00 00 0A 5F
  					// VESA Setting
 					39 00 00 40 00 00 02 90 03
 					39 00 00 40 00 00 02 6F 01
 					39 00 00 40 00 00 02 90 43
 					39 00 00 40 00 00 13 91 89 28 00 10 C2 00 02 32 01 9C 00 08 06 67 05 92 10 E0
 					// DC 120Hz
 					39 00 00 40 00 00 02 2F 30
 					39 00 00 00 00 00 02 6D 00
 					// TE On
 					39 00 00 00 00 00 02 35 00
 					// DBV = 0
					39 00 00 00 00 00 03 51 00 00
					// idle_dimming_dbv = 0
					39 00 00 40 00 00 02 6F 04
					39 00 00 00 00 00 03 51 00 00
					// BCTRL = 1, DD = 0
					39 00 00 00 00 00 02 53 20
					// 0x00 Data remap off 0x0F Data remap on
					39 00 00 40 00 00 06 F0 55 AA 52 08 00
					39 00 00 40 00 00 02 6F 02
					39 00 00 40 00 00 02 B2 0F
 					// Skip mode setting
					39 00 00 40 00 00 04 8C 00 00 10
					39 00 00 40 00 00 03 5A 00 00
					39 00 00 00 00 00 02 2F 30
					// AP SPR
					39 00 00 40 00 00 06 F0 55 AA 52 08 03
					39 00 00 40 00 00 02 6F 09
					39 00 00 40 00 00 07 DE 10 34 25 30 14 25
					39 00 00 40 00 00 06 F0 55 AA 52 08 07
					39 00 00 40 00 00 06 B0 84 44 00 00 40
					39 00 00 40 00 00 07 B1 18 08 00 08 18 00
					39 00 00 00 00 00 13 91 AB F0 00 10 C1 00 01 CB 00 73 00 33 06 67 1F B0 11 40
					// Still = 0 VDO no RAM
					39 00 00 00 00 00 02 18 00
					// GPO2 = Vsync
					39 00 00 40 00 00 06 F0 55 AA 52 08 00
					39 00 00 40 00 00 02 6F 02
 					39 00 00 40 00 00 03 BE 4F 4A
 					39 00 00 40 00 00 02 6F 0A
 					39 00 00 00 00 00 02 BE 02
 					// VDO with RAM
 					39 00 00 40 00 00 06 F0 55 AA 52 08 01
 					39 00 00 40 00 00 02 6F 17
 					39 00 00 00 00 00 02 B8 07
 					// GMA By Frame
 					39 00 00 40 00 00 06 F0 55 AA 52 08 02
 					39 00 00 00 00 00 02 CC 10
					// Idle Mode porch
					39 00 00 40 00 00 05 FF AA 55 A5 81
					39 00 00 40 00 00 02 6F 0F
					39 00 00 00 00 00 02 F5 0E
					// Demura on
					39 00 00 40 00 00 06 F0 55 AA 52 08 04
					39 00 00 00 00 00 02 CA 01
					// A3 Setting
					39 00 00 40 00 00 06 F0 55 AA 52 08 04
					39 00 00 40 00 00 02 6F 06
					39 00 00 40 00 00 02 B5 00
					39 00 00 40 00 00 05 FF AA 55 A5 81
					39 00 00 40 00 00 02 6F 0D
					39 00 00 40 00 00 02 FD 40
					39 00 00 40 00 00 07 51 00 00 00 00 00 00
					39 00 00 00 00 00 06 A3 84 02 5F 02 5F
					// osc trace
					39 00 00 40 00 00 06 F0 55 AA 52 08 01
					39 00 00 40 00 00 37 C3 00 00 00 00 EA 00 00 00 00 EA 00 00 00 00 00 00 00 00 00 00 00 00 00 00 00 00 00 00 00 00 00 00 00 00 00 00 00 00 00 00 00 00 00 00 00 00 00 11 00 AA 02 AA 02 00
					39 00 00 00 00 00 24 EA 11 02 3C 00 0D 0B 0A 01 7C 00 00 11 02 3C 00 0D 0B 0A 01 A7 00 00 00 00 00 00 01 7C 01 A7 00 0C 00 00 40
					//vdo drop=1.1s
					39 00 00 40 00 00 06 F0 55 AA 52 08 03
					15 00 00 40 00 00 02 6F 1D
					15 00 00 40 00 00 02 C6 0C
					//0xB4AA=4583  46250*8*3=1.1S
					15 00 00 40 00 00 02 6F 2C
					39 00 00 00 00 00 07 C6 AA B4 AA B4 AA B4
					// Sleep Out
					05 00 00 00 78 00 01 11
					// expand demura lut 16DBV*7Gray
					39 00 00 40 00 00 13 A3 84 02 5F 02 5F 02 04 B5 02 03 00 03 00 00 00 00 00 00
					39 00 00 40 00 00 02 6F 12
					39 00 00 40 00 00 0E A3 01 00 9D 00 00 AA 00 00 00 00 00 00 00
					39 00 00 40 00 00 02 6F 53
					39 00 00 40 00 00 0E A3 02 04 B5 02 03 00 0C 00 00 00 00 00 00
					39 00 00 40 00 00 02 6F 60
					39 00 00 00 00 00 0E A3 01 00 9D 00 00 AA 00 00 00 00 00 00 00
					// Display On
					05 00 00 00 00 00 01 29
					// ESD ERR Flag on
					39 00 00 40 00 00 06 F0 55 AA 52 08 00
					15 00 00 40 00 00 02 6F 05
					15 00 00 00 00 00 02 BE 08

					// VHM Setting
					// opt_level2_te_fall=1,Level TE drop position reference multi-TE
					39 01 00 40 00 00 04 8D 00 20 00
					15 01 00 40 00 00 02 6F 8A
					15 01 00 40 00 00 02 44 19
					39 01 00 40 00 00 06 F0 55 AA 52 08 00
					39 01 00 40 00 00 03 BE 47 45
					// Level_TE(0x6A)、ARP(0x77)、Test_TE(0x7D)
					15 01 00 40 00 00 02 6F 14
					39 01 00 40 00 00 04 35 6A 77 E0
					15 01 00 40 00 00 02 6F 17
					39 01 00 40 00 00 04 35 6A 77 E0
					15 01 00 40 00 00 02 6F 1A
					39 01 00 40 00 00 04 35 6A 77 E0
					15 01 00 40 00 00 02 6F 1D
					39 01 00 40 00 00 04 35 6A 77 E0
					// dyn_multi_te_start[13:0]adjust TE left
					15 01 00 40 00 00 02 6F 26
					39 01 00 40 00 00 03 44 00 78
					// dyn_multi_te_start_skip[13:0]adjust TE left
					15 01 00 40 00 00 02 6F 28
					39 01 00 40 00 00 03 44 00 78
					// dyn_multi_te_start_video[13:0]adjust TE left
					15 01 00 40 00 00 02 6F 42
					39 01 00 40 00 00 03 44 00 78
					// dyn_multi_te_start_vdo_skip[13:0]adjust TE left
					15 01 00 40 00 00 02 6F 64
					39 01 00 40 00 00 03 44 00 78
					// dyn_multi_te_width[7:0]
					15 01 00 40 00 00 02 6F 2A
					15 01 00 40 00 00 02 44 1A
					// dyn_multi_te_interval[13:0]=2736
					15 01 00 40 00 00 02 6F 2B
					39 01 00 40 00 00 03 44 0A B0
					// TE07_DPU_DELAY[7:0]
					15 01 00 40 00 00 02 6F 02
					15 01 00 40 00 00 02 35 18
					// SEL_ECK_CYCLE_LINE=0,EXTEND_VFP_LINE_ECLK_EN=0
					39 01 00 40 00 00 06 F0 55 AA 52 08 00
					15 01 00 40 00 00 02 6F 04
					15 01 00 40 00 00 02 BA 00
					// TE07_DPU_DELAY_VDO[7:0]
					15 01 00 40 00 00 02 6F 0C
					15 01 00 40 00 00 02 35 00
					// set_dsi_mode=1
					15 01 00 40 00 00 02 71 01
					// still=1
					15 01 00 40 00 00 02 18 00
					// REGW 0x6D,0x04
					// EXT_HSYNC_EN=1
					39 01 00 40 00 00 06 F0 55 AA 52 08 03
					15 01 00 40 00 00 02 6F 06
					15 01 00 40 00 00 02 BA 01
					// DFC_mode3
					39 01 00 40 00 00 04 2F 30 05 30
					// ARP_TE selects TE1F
					39 01 00 40 00 00 06 F0 55 AA 52 08 00
					15 01 00 40 00 00 02 6F 35
					15 01 00 40 00 00 02 B1 10
					39 01 00 40 00 00 06 F0 55 AA 52 08 00
					// opt_dis_vdo_ltpo_crc=1(Disable CRC calculation), 0 (default: calculate CRC)
					15 01 00 40 00 00 02 6F DD
					15 01 00 40 00 00 02 BA 80
					// FD fixedly retreats one line
					39 01 00 40 00 00 06 F0 55 AA 52 08 08
					15 01 00 40 00 00 02 6F 02
					15 01 00 40 00 00 02 E0 81
					// 20250514
					// opt_v2c_chg_reload_fskip=1:Set skip frame_skip to return EM to sequence 1 without skipping the sequence
					// opt_v2c_chg_reload_fskip=0:Jump out of sequence
					// opt_level2_te_fall=1(707A only) _wrote about deletion before
					// REGW 0x6F,0x8A
					// REGW 0x44,0x11
					// 20BAE2[3]=1，V2C receives the outbound VSS and requests sequence 1 back (this question assumes that the V2C VSS follows the TE and does not generate an ARP, which would allow the VSS to match the TE's response)
					39 01 00 40 00 00 06 F0 55 AA 52 08 00
					15 01 00 40 00 00 02 6F E2
					15 01 00 40 00 00 02 BA 08
					// 31FB00[4]=1，By default, the frame sent to V2C will not use extd_vfp. When vcnt_val_clr is seen, v is generated. Setting opt_rgb_v_gate_afp=1 will make the V2C frame also use extd_vfp
					39 01 00 40 00 00 05 FF AA 55 A5 81
					15 01 00 40 00 00 02 6F 00
					15 01 00 40 00 00 02 FB 10
					// CMD3,Page1
					// Enable the VESA CLK function to stop CLK in the skip frame. VESA CLK will still be enabled by MIPI writing
					39 01 00 40 00 00 05 FF AA 55 A5 81
					15 01 00 40 00 00 02 6F 1C
					15 01 00 40 00 00 02 FB 10
					// 707A_P3_Y=2736，Xiaomi P3_VHM, still=1, using TE2 to achieve ALS 60Hz
					// TE_RW_rising_command mode
					// dyn_multi_te_start=dyn_multi_te_start_skip=0x1A/ =dyn_multi_te_width=0x1A/dyn_multi_te_interval=0x1560
					15 01 00 40 00 00 02 6F 2D
					39 01 00 40 00 00 08 44 00 1A 00 1A 1A 15 60
					// dyn_multi_te_start=dyn_multi_te_start_skip=0x1A/ =dyn_multi_te_width=0x1A/dyn_multi_te_interval=0x1560
					15 01 00 40 00 00 02 6F 3B
					39 01 00 40 00 00 08 44 00 1A 00 1A 1A 15 60
					// 707A
					15 01 00 40 00 00 02 6F 69
					15 01 00 00 00 00 02 44 02
					// TE20_sel_cmd=7D(Test TE)
					// REGW 0x6F,0x16
					// REGW 0x35,0xE0
					// REGW 0x6F,0x19
					// REGW 0x35,0xE0
					// REGW 0x6F,0x1C
					// REGW 0x35,0xE0
					// REGW 0x6F,0x1F
					// REGW 0x35,0xE0
					//120Hz PWM Skip Frame Rate
					39 01 00 40 00 00 06 F0 55 AA 52 08 00
					15 01 00 40 00 00 02 6F B8
					39 01 00 40 00 00 09 BA 22 22 22 22 22 22 22 21
					15 01 00 40 00 00 02 6F C0
					39 01 00 40 00 00 09 BA 22 22 22 22 22 22 22 21
					15 01 00 40 00 00 02 6F 5A
					39 01 00 40 00 00 09 D1 22 22 22 22 22 22 22 21
					15 01 00 40 00 00 02 6F 31
					15 01 00 40 00 00 02 C0 02
					39 01 00 40 00 00 19 A9 01 00 2F 00 00 32 02 01 B9 32 32 6D 01 00 A2 00 06 05 02 01 B9 32 32 26
					39 01 00 40 00 00 13 A3 84 02 5F 02 5F 02 04 B5 02 03 00 12 00 00 00 00 00 00
					15 01 00 40 00 00 02 6F 12
					39 01 00 40 00 00 0E A3 01 00 9D 00 00 AA 00 00 00 00 00 00 00
					15 01 00 40 00 00 02 6F 53
					39 01 00 40 00 00 0E A3 02 04 B5 02 03 00 24 00 00 00 00 00 00
					15 01 00 40 00 00 02 6F 60
					39 01 00 40 00 00 0E A3 01 00 9D 00 00 AA 00 00 00 00 00 00 00
					// PWM mode 120 /90 PWM/skip frame rate
					39 01 00 40 00 00 06 F0 55 AA 52 08 08
					39 01 00 40 00 00 11 B6 09 D7 09 D7 09 D7 09 D7 09 D7 09 D7 09 D7 09 D7
					15 01 00 40 00 00 02 6F 10
					39 01 00 40 00 00 11 B6 09 D7 09 D7 09 D7 09 D7 0E 27 0E 27 0E 27 0E 27
					15 01 00 40 00 00 02 6F 20
					39 01 00 40 00 00 0F B6 0E 27 0E 27 0E 27 0E 27 0F FF 0F FF 0F FF
					39 01 00 40 00 00 11 B7 00 00 00 00 00 00 00 00 00 00 00 00 00 00 00 00
					15 01 00 40 00 00 02 6F 10
					39 01 00 40 00 00 11 B7 00 00 00 00 00 00 00 00 00 00 00 00 08 00 08 00
					15 01 00 40 00 00 02 6F 20
					39 01 00 40 00 00 0F B7 06 38 06 38 06 68 06 68 06 9A 06 9A 08 00
					//120hz PWM mode
					39 01 00 40 00 00 06 F0 55 AA 52 08 01
					15 01 00 40 00 00 02 6F 0E
					39 01 00 40 00 00 05 B8 D8 88 D8 88
					39 01 00 40 00 00 06 F0 55 AA 52 08 05
					15 01 00 40 00 00 02 6F 03
					15 01 00 40 00 00 02 E1 03
					//od PWM
					39 01 00 40 00 00 06 F0 55 AA 52 08 08
					15 01 00 40 00 00 02 6F 0E
					39 01 00 40 00 00 0F E1 01 02 03 04 04 04 04 04 05 05 05 05 05 04
					39 01 00 40 00 00 0F E2 0C 10 18 2D 2D 2D 2D 2A 28 30 35 1F 1A 0D   
					15 01 00 40 00 00 02 6F 0E
					39 01 00 40 00 00 0F E2 06 0C 11 28 25 25 25 23 21 1C 11 0F 0D 0B
					15 01 00 40 00 00 02 6F 1C
					39 01 00 40 00 00 0F E2 06 0C 11 15 13 13 18 16 14 11 0E 0D 0A 09
					15 01 00 40 00 00 02 6F 2A
					39 01 00 40 00 00 0F E2 03 06 0A 0E 0D 0B 0D 0D 0C 0A 0A 0A 08 07
					15 01 00 40 00 00 02 6F 38
					39 01 00 40 00 00 0F E2 02 03 05 0C 0B 08 09 09 0A 09 09 09 07 06
					15 01 00 40 00 00 02 6F 46
					39 01 00 40 00 00 0F E2 02 02 03 0A 09 08 09 0A 0B 0C 0C 0F 11 16
					15 01 00 40 00 00 02 6F 54
					39 01 00 40 00 00 0F E2 02 02 03 0B 0A 08 09 0A 0B 0C 0C 0F 11 16
					15 01 00 40 00 00 02 6F 62
					39 01 00 40 00 00 0F E2 01 02 03 04 04 05 07 08 09 0A 0D 10 11 16
					15 01 00 40 00 00 02 6F 1B
					39 01 00 40 00 00 07 EB 34 E0 00 05 00 00
					// VHM setting,common first and then 6D
					// PWM
					15 01 00 40 00 00 02 6F 2B
					39 01 00 40 00 00 03 44 03 90
					// PWM 1HZ
					39 01 00 40 00 00 06 F0 55 AA 52 08 00
					15 01 00 40 00 00 02 6F 0E
					15 01 00 40 00 00 02 C0 00
					15 01 00 40 00 00 02 6F DE
					15 01 00 40 00 00 02 BA 00
					15 01 00 40 00 00 02 6F 04
					15 01 00 40 00 00 02 35 00
					15 01 00 40 00 00 02 6F 14
					15 01 00 40 00 00 02 35 6A
					39 01 00 40 00 00 03 44 0A 60
					15 01 00 40 00 00 02 8C 02
					15 01 00 40 00 00 02 6D 87
					// reload demura
					39 01 00 40 00 00 06 F0 55 AA 52 08 04
					15 01 00 40 00 00 02 6F 02
					39 01 00 40 00 00 03 B5 00 12
					15 01 00 00 00 00 02 9D AA
				];
				qcom,mdss-dsi-on-command-state = "dsi_lp_mode";

				qcom,mdss-dsi-esync-post-on-commands = [
					39 01 00 40 00 00 06 F0 55 AA 52 08 03
					39 01 00 40 00 00 02 6F 06
					// 00 -> MIPI Hsync  01 -> Ext Hsync
					39 01 00 00 00 00 02 BA 01
				];
				qcom,mdss-dsi-esync-post-on-commands-state = "dsi_hs_mode";

				qcom,mdss-dsi-qsync-freq-step-sequence-interval =
					<0 120000 1>, <0 60000 1>, <1 120000 1>, <1 60000 1>;
				qcom,mdss-dsi-qsync-freq-step-sequence  =
					<30000 1>,
					<30000 1>,
					<30000 1>,
					<30000 1>;

				qcom,mdss-dsi-sticky_still_en-command = [
					39 01 00 00 00 00 1A A9 01 00 18 00 00 01 02 00 D1 6E 6F 3F F0 02 00 BE 02 02 60 01 00 44 69 69 02
				];
				qcom,mdss-dsi-sticky_still_disable-command = [
					39 01 00 00 00 00 1A A9 01 00 18 00 00 00 02 00 D1 6E 6F FF FF 02 00 BE 02 02 47 01 00 44 69 69 00
				];
				qcom,mdss-dsi-sticky_still_en-command-state = "dsi_lp_mode";
				qcom,mdss-dsi-sticky_still_disable-command-state = "dsi_lp_mode";

				qcom,mdss-dsi-qsync-freq-pattren-needs-selfrefresh =
					<1 1 1 1>;

				qcom,mdss-dsi-freq-step-pattern1-command = [
					// Non Cmd Setting
					39 01 00 00 00 00 06 F0 55 AA 52 08 00
				];
				qcom,mdss-dsi-freq-step-pattern1-command-state = "dsi_lp_mode";

				qcom,mdss-dsi-freq-step-pattern2-command = [
					// Non Cmd Setting
					39 01 00 00 00 00 06 F0 55 AA 52 08 00
				];
				qcom,mdss-dsi-freq-step-pattern2-command-state = "dsi_lp_mode";

				qcom,mdss-dsi-freq-step-pattern3-command = [
					// Non Cmd Setting
					39 01 00 00 00 00 06 F0 55 AA 52 08 00
				];
				qcom,mdss-dsi-freq-step-pattern3-command-state = "dsi_lp_mode";

				qcom,mdss-dsi-freq-step-pattern4-command = [
					// Non Cmd Setting
					39 01 00 00 00 00 06 F0 55 AA 52 08 00
				];
				qcom,mdss-dsi-freq-step-pattern4-command-state = "dsi_lp_mode";

				qcom,mdss-dsi-em-pulse-switch-command = [
					//120Hz PWM Skip Frame Rate
					39 01 00 40 00 00 06 F0 55 AA 52 08 00
					15 01 00 40 00 00 02 6F B8
					39 01 00 40 00 00 09 BA 22 22 22 22 22 22 22 21
					15 01 00 40 00 00 02 6F C0
					39 01 00 40 00 00 09 BA 22 22 22 22 22 22 22 21
					15 01 00 40 00 00 02 6F 5A
					39 01 00 40 00 00 09 D1 22 22 22 22 22 22 22 21
					15 01 00 40 00 00 02 6F 31
					15 01 00 40 00 00 02 C0 02
					39 01 00 40 00 00 19 A9 01 00 2F 00 00 32 02 01 B9 32 32 6D 01 00 A2 00 06 05 02 01 B9 32 32 26
					39 01 00 40 00 00 13 A3 84 02 5F 02 5F 02 04 B5 02 03 00 12 00 00 00 00 00 00
					15 01 00 40 00 00 02 6F 12
					39 01 00 40 00 00 0E A3 01 00 9D 00 00 AA 00 00 00 00 00 00 00
					15 01 00 40 00 00 02 6F 53
					39 01 00 40 00 00 0E A3 02 04 B5 02 03 00 24 00 00 00 00 00 00
					15 01 00 40 00 00 02 6F 60
					39 01 00 40 00 00 0E A3 01 00 9D 00 00 AA 00 00 00 00 00 00 00
					// PWM mode 120 /90 PWM/skip frame rate
					39 01 00 40 00 00 06 F0 55 AA 52 08 08
					39 01 00 40 00 00 11 B6 09 D7 09 D7 09 D7 09 D7 09 D7 09 D7 09 D7 09 D7
					15 01 00 40 00 00 02 6F 10
					39 01 00 40 00 00 11 B6 09 D7 09 D7 09 D7 09 D7 0E 27 0E 27 0E 27 0E 27
					15 01 00 40 00 00 02 6F 20
					39 01 00 40 00 00 0F B6 0E 27 0E 27 0E 27 0E 27 0F FF 0F FF 0F FF
					39 01 00 40 00 00 11 B7 00 00 00 00 00 00 00 00 00 00 00 00 00 00 00 00
					15 01 00 40 00 00 02 6F 10
					39 01 00 40 00 00 11 B7 00 00 00 00 00 00 00 00 00 00 00 00 08 00 08 00
					15 01 00 40 00 00 02 6F 20
					39 01 00 40 00 00 0F B7 06 38 06 38 06 68 06 68 06 9A 06 9A 08 00
					//120hz PWM mode
					39 01 00 40 00 00 06 F0 55 AA 52 08 01
					15 01 00 40 00 00 02 6F 0E
					39 01 00 40 00 00 05 B8 D8 88 D8 88
					39 01 00 40 00 00 06 F0 55 AA 52 08 05
					15 01 00 40 00 00 02 6F 03
					15 01 00 40 00 00 02 E1 03
					//od PWM
					39 01 00 40 00 00 06 F0 55 AA 52 08 08
					15 01 00 40 00 00 02 6F 0E
					39 01 00 40 00 00 0F E1 01 02 03 04 04 04 04 04 05 05 05 05 05 04
					39 01 00 40 00 00 0F E2 0C 10 18 2D 2D 2D 2D 2A 28 30 35 1F 1A 0D   
					15 01 00 40 00 00 02 6F 0E
					39 01 00 40 00 00 0F E2 06 0C 11 28 25 25 25 23 21 1C 11 0F 0D 0B
					15 01 00 40 00 00 02 6F 1C
					39 01 00 40 00 00 0F E2 06 0C 11 15 13 13 18 16 14 11 0E 0D 0A 09
					15 01 00 40 00 00 02 6F 2A
					39 01 00 40 00 00 0F E2 03 06 0A 0E 0D 0B 0D 0D 0C 0A 0A 0A 08 07
					15 01 00 40 00 00 02 6F 38
					39 01 00 40 00 00 0F E2 02 03 05 0C 0B 08 09 09 0A 09 09 09 07 06
					15 01 00 40 00 00 02 6F 46
					39 01 00 40 00 00 0F E2 02 02 03 0A 09 08 09 0A 0B 0C 0C 0F 11 16
					15 01 00 40 00 00 02 6F 54
					39 01 00 40 00 00 0F E2 02 02 03 0B 0A 08 09 0A 0B 0C 0C 0F 11 16
					15 01 00 40 00 00 02 6F 62
					39 01 00 40 00 00 0F E2 01 02 03 04 04 05 07 08 09 0A 0D 10 11 16
					15 01 00 40 00 00 02 6F 1B
					39 01 00 40 00 00 07 EB 34 E0 00 05 00 00
					// VHM setting,common first and then 6D
					// PWM
					15 01 00 40 00 00 02 6F 2B
					39 01 00 40 00 00 03 44 03 90
					// PWM 1HZ
					39 01 00 40 00 00 06 F0 55 AA 52 08 00
					15 01 00 40 00 00 02 6F 0E
					15 01 00 40 00 00 02 C0 00
					15 01 00 40 00 00 02 6F DE
					15 01 00 40 00 00 02 BA 00
					15 01 00 40 00 00 02 6F 04
					15 01 00 40 00 00 02 35 00
					15 01 00 40 00 00 02 6F 14
					15 01 00 40 00 00 02 35 6A
					39 01 00 40 00 00 03 44 0A 60
					15 01 00 40 00 00 02 8C 02
					15 01 00 40 00 00 02 6D 87
					//707A_P3_Y=2736，Xiaomi P3_VHM, still=1, using TE2 to achieve ALS 90Hz
					//TE_RW_rising_command mode
					//dyn_multi_te_start=dyn_multi_te_start_skip=0x1A/ =dyn_multi_te_width=0x1A/dyn_multi_te_interval=0x1008
					15 01 00 40 00 00 02 6F 2D
					39 01 00 40 00 00 08 44 00 1A 00 1A 1A 15 60
					//dyn_multi_te_start=dyn_multi_te_start_skip=0x1A/ =dyn_multi_te_width=0x1A/dyn_multi_te_interval=0x1008
					15 01 00 40 00 00 02 6F 3B
					39 01 00 00 00 00 08 44 00 1A 00 1A 1A 15 60
				];
				qcom,mdss-dsi-em-pulse-switch-command-state = "dsi_hs_mode";

				mi,mdss-dsi-em-pulse-supplement-switch-command = [
					//120Hz PWM Skip Frame Rate
					39 01 00 40 00 00 06 F0 55 AA 52 08 00
					15 01 00 40 00 00 02 6F B8
					39 01 00 40 00 00 09 BA 22 22 22 22 22 22 22 21
					15 01 00 40 00 00 02 6F C0
					39 01 00 40 00 00 09 BA 22 22 22 22 22 22 22 21
					15 01 00 40 00 00 02 6F 5A
					39 01 00 40 00 00 09 D1 22 22 22 22 22 22 22 21
					15 01 00 40 00 00 02 6F 31
					15 01 00 40 00 00 02 C0 02
					39 01 00 40 00 00 19 A9 01 00 2F 00 00 32 02 01 B9 32 32 6D 01 00 A2 00 06 05 02 01 B9 32 32 26
					39 01 00 40 00 00 13 A3 84 02 5F 02 5F 02 04 B5 02 03 00 12 00 00 00 00 00 00
					15 01 00 40 00 00 02 6F 12
					39 01 00 40 00 00 0E A3 01 00 9D 00 00 AA 00 00 00 00 00 00 00
					15 01 00 40 00 00 02 6F 53
					39 01 00 40 00 00 0E A3 02 04 B5 02 03 00 24 00 00 00 00 00 00
					15 01 00 40 00 00 02 6F 60
					39 01 00 40 00 00 0E A3 01 00 9D 00 00 AA 00 00 00 00 00 00 00
					// PWM mode 120 /90 PWM/skip frame rate
					39 01 00 40 00 00 06 F0 55 AA 52 08 08
					39 01 00 40 00 00 11 B6 09 D7 09 D7 09 D7 09 D7 09 D7 09 D7 09 D7 09 D7
					15 01 00 40 00 00 02 6F 10
					39 01 00 40 00 00 11 B6 09 D7 09 D7 09 D7 09 D7 0E 27 0E 27 0E 27 0E 27
					15 01 00 40 00 00 02 6F 20
					39 01 00 40 00 00 0F B6 0E 27 0E 27 0E 27 0E 27 0F FF 0F FF 0F FF
					39 01 00 40 00 00 11 B7 00 00 00 00 00 00 00 00 00 00 00 00 00 00 00 00
					15 01 00 40 00 00 02 6F 10
					39 01 00 40 00 00 11 B7 00 00 00 00 00 00 00 00 00 00 00 00 08 00 08 00
					15 01 00 40 00 00 02 6F 20
					39 01 00 40 00 00 0F B7 06 38 06 38 06 68 06 68 06 9A 06 9A 08 00
					//120hz PWM mode
					39 01 00 40 00 00 06 F0 55 AA 52 08 01
					15 01 00 40 00 00 02 6F 0E
					39 01 00 40 00 00 05 B8 D8 88 D8 88
					39 01 00 40 00 00 06 F0 55 AA 52 08 05
					15 01 00 40 00 00 02 6F 03
					15 01 00 40 00 00 02 E1 03
					//od PWM
					39 01 00 40 00 00 06 F0 55 AA 52 08 08
					15 01 00 40 00 00 02 6F 0E
					39 01 00 40 00 00 0F E1 01 02 03 04 04 04 04 04 05 05 05 05 05 04
					39 01 00 40 00 00 0F E2 0C 10 18 2D 2D 2D 2D 2A 28 30 35 1F 1A 0D
					15 01 00 40 00 00 02 6F 0E
					39 01 00 40 00 00 0F E2 06 0C 11 28 25 25 25 23 21 1C 11 0F 0D 0B
					15 01 00 40 00 00 02 6F 1C
					39 01 00 40 00 00 0F E2 06 0C 11 15 13 13 18 16 14 11 0E 0D 0A 09
					15 01 00 40 00 00 02 6F 2A
					39 01 00 40 00 00 0F E2 03 06 0A 0E 0D 0B 0D 0D 0C 0A 0A 0A 08 07
					15 01 00 40 00 00 02 6F 38
					39 01 00 40 00 00 0F E2 02 03 05 0C 0B 08 09 09 0A 09 09 09 07 06
					15 01 00 40 00 00 02 6F 46
					39 01 00 40 00 00 0F E2 02 02 03 0A 09 08 09 0A 0B 0C 0C 0F 11 16
					15 01 00 40 00 00 02 6F 54
					39 01 00 40 00 00 0F E2 02 02 03 0B 0A 08 09 0A 0B 0C 0C 0F 11 16
					15 01 00 40 00 00 02 6F 62
					39 01 00 40 00 00 0F E2 01 02 03 04 04 05 07 08 09 0A 0D 10 11 16
					15 01 00 40 00 00 02 6F 1B
					39 01 00 40 00 00 07 EB 34 E0 00 05 00 00
					// VHM setting,common first and then 6D
					// PWM
					15 01 00 40 00 00 02 6F 2B
					39 01 00 40 00 00 03 44 03 90
					// PWM 1HZ
					39 01 00 40 00 00 06 F0 55 AA 52 08 00
					15 01 00 40 00 00 02 6F 0E
					15 01 00 40 00 00 02 C0 00
					15 01 00 40 00 00 02 6F DE
					15 01 00 40 00 00 02 BA 00
					15 01 00 40 00 00 02 6F 04
					15 01 00 40 00 00 02 35 00
					15 01 00 40 00 00 02 6F 14
					15 01 00 40 00 00 02 35 6A
					39 01 00 40 00 00 03 44 0A 60
					15 01 00 40 00 00 02 8C 02
					15 01 00 40 00 00 02 6D 87
					//707A_P3_Y=2736，Xiaomi P3_VHM, still=1, using TE2 to achieve ALS 90Hz
					//TE_RW_rising_command mode
					//dyn_multi_te_start=dyn_multi_te_start_skip=0x1A/ =dyn_multi_te_width=0x1A/dyn_multi_te_interval=0x1008
					15 01 00 40 00 00 02 6F 2D
					39 01 00 40 00 00 08 44 00 1A 00 1A 1A 15 60
					//dyn_multi_te_start=dyn_multi_te_start_skip=0x1A/ =dyn_multi_te_width=0x1A/dyn_multi_te_interval=0x1008
					15 01 00 40 00 00 02 6F 3B
					39 01 00 00 00 00 08 44 00 1A 00 1A 1A 15 60
				];
				mi,mdss-dsi-em-pulse-supplement-switch-command-state = "dsi_hs_mode";

				mi,mdss-dsi-demura-over-threshold-command = [
					39 01 00 40 00 00 06 F0 55 AA 52 08 04
					15 01 00 40 00 00 02 6F 02
					39 01 00 40 00 00 03 B5 00 24
					15 01 00 00 00 00 02 9D AA
				];
				mi,mdss-dsi-demura-over-threshold-command-state = "dsi_hs_mode";

				mi,mdss-dsi-demura-under-threshold-command = [
					39 01 00 40 00 00 06 F0 55 AA 52 08 04
					15 01 00 40 00 00 02 6F 02
					39 01 00 40 00 00 03 B5 00 12
					15 01 00 00 00 00 02 9D AA
				];
				mi,mdss-dsi-demura-under-threshold-command-state = "dsi_hs_mode";
			};

			timing@wqhd_normal_90hz_index_02 {
				#include "dsi-panel-p3-42-02-0a-mp-dsc-vhm-pmic-b-common.dtsi"

				cell-index = <2>;
				qcom,mdss-dsi-panel-framerate = <90>;
				qcom,mdss-dsi-v-front-porch = <965>;
				qcom,mdss-dsi-h-front-porch = <54>;

				qcom,mdss-esync-hsync-milli-pulse-width = <600>;
				qcom,mdss-esync-emsync-milli-pulse-width = <300>;
				qcom,mdss-esync-emsync-fps = <90>;
				qcom,dsi-qsync-mode-avr-step-fps = <90>;
				qcom,qsync-mode-min-refresh-rate = <30>;

				mi,mdss-dsi-current-timming-is-dc-mode = <1>;

				qcom,mdss-dsi-on-command = [
					// LCTC ON
					39 00 00 40 00 00 06 F0 55 AA 52 08 08
					15 00 00 40 00 00 02 BF 21
					// ACTC ON
					15 00 00 40 00 00 02 6F B7
					15 00 00 00 00 00 02 BF 11
					// Power Domain
					39 00 00 40 00 00 06 F0 55 AA 52 08 01
					15 00 00 40 00 00 02 6F 49
					39 00 00 00 00 00 06 B9 01 22 00 EE EE
					// AOD pump
					39 00 00 40 00 00 06 F0 55 AA 52 08 01
					39 00 00 00 00 00 05 B2 00 00 FF 03
					// Data chopper setting
					39 00 00 40 00 00 06 F0 55 AA 52 08 01
					15 00 00 40 00 00 02 6F 23
					39 00 00 00 00 00 04 D9 CB 49 13
					// EM TH2 Duty Setting
					39 00 00 40 00 00 06 F0 55 AA 52 08 00
					39 00 00 40 00 00 02 6F 21
					39 00 00 40 00 00 09 B2 00 28 00 28 00 3C 00 28
					39 00 00 40 00 00 02 6F 75
					39 00 00 40 00 00 09 B2 00 28 00 28 00 3C 00 28
					39 00 00 40 00 00 02 6F 71
					39 00 00 00 00 00 03 B2 00 28
					// PMIC Fast discharge
 					39 00 00 40 00 00 02 6F 51
 					39 00 00 40 00 00 02 D5 02
 					39 00 00 40 00 00 02 6F 54
 					39 00 00 00 00 00 02 D5 1F
 					// Switch VGMP by Fcon
 					39 00 00 40 00 00 06 F0 55 AA 52 08 01
 					39 00 00 40 00 00 02 6F 16 
 					39 00 00 00 00 00 05 C6 87 22 2C 2C
 					// demura,FLASH CODE
					39 00 00 40 00 00 06 F0 55 AA 52 08 00
					39 00 00 40 00 00 02 C7 44
					39 00 00 40 00 00 02 6F 31 
					39 00 00 40 00 00 03 C0 00 20
					39 00 00 40 00 00 02 6F 06 
					39 00 00 40 00 00 03 C7 60 60
					39 00 00 40 00 00 02 6F 08 
					39 00 00 40 00 00 03 C7 66 26
					39 00 00 40 00 00 06 F0 55 AA 52 08 04
					39 00 00 00 00 00 02 C0 20
 					// SVM
 					39 00 00 40 00 00 06 F0 55 AA 52 08 00
 					39 00 00 40 00 00 02 6F 20
 					39 00 00 40 00 00 02 B2 03
 					39 00 00 40 00 00 06 F0 55 AA 52 08 01
 					39 00 00 40 00 00 02 6F F0
 					39 00 00 40 00 00 02 C0 F1
 					39 00 00 40 00 00 02 6F F1
 					39 00 00 40 00 00 03 C0 12 12
 					39 00 00 40 00 00 02 6F F4
  					39 00 00 40 00 00 03 C0 12 12
  					39 00 00 40 00 00 02 6F 01
  					39 00 00 40 00 00 04 CE 00 00 00
  					39 00 00 40 00 00 02 6F 94
  					39 00 00 40 00 00 04 E2 00 11 00
  					39 00 00 40 00 00 02 6F 24
  					39 00 00 40 00 00 13 E5 42 8C 94 90 92 07 42 8C 94 90 92 07 42 8C 94 90 92 07
  					39 00 00 40 00 00 02 6F A7
  					39 00 00 40 00 00 02 E7 C0
  					39 00 00 40 00 00 02 6F DA
 					39 00 00 40 00 00 03 E7 00 00
 					39 00 00 40 00 00 06 F0 55 AA 52 08 01
 					39 00 00 40 00 00 02 6F E3
 					39 00 00 00 00 00 18 E5 FF FF FF FF 9B 9B 61 61 4D 4D 3A 3A 00 00 00 00 00 00 00 00 00 00 00
 					// APL,Normal 32,HBM 8,APL 0
 					39 00 00 40 00 00 06 F0 55 AA 52 08 00
 					39 00 00 40 00 00 02 6F 78
 					39 00 00 40 00 00 18 B0 11 00 2A 00 C2 01 DA 03 7C 05 B1 08 80 0B EE 0F FF 05 55 05 56 05 55
 					39 00 00 40 00 00 02 6F 6F
 					39 00 00 40 00 00 07 B0 02 62 04 C4 02 62
 					39 00 00 40 00 00 06 F0 55 AA 52 08 08
 					39 00 00 40 00 00 17 C1 9C FF CC FF FF CC FF FF CC FF FF DC FF FF DD FF FF FF 7F FF 0E FF
 					39 00 00 40 00 00 02 6F 1D
 					39 00 00 40 00 00 07 C1 00 FF FF 4F 00 FF
 					39 00 00 40 00 00 02 6F 23
 					39 00 00 40 00 00 15 C1 0C FF CC FF FF CC FF FF CC FF FF DC FF FF DD FF FF CF 7F 67
 					39 00 00 40 00 00 02 6F 37
 					39 00 00 40 00 00 15 C1 0C FF CC FF FF CC FF FF CC FF FF DC FF FF DD FF FF FF 7F FF
 					39 00 00 40 00 00 02 6F 4B
 					39 00 00 00 00 00 15 C1 0C FF CC FF FF CC FF FF CC FF FF DC FF FF DD FF FF CF 7F 67
  					// Data Scaling DBV_TH
  					39 00 00 00 00 00 2D BA 00 07 00 26 00 26 00 64 00 64 00 AC 00 AC 01 26 01 26 02 5F 02 5F 02 60 02 60 07 FB 07 FB 17 FE 17 FE 1F FF 1F FF 34 BC 34 BC 3F FE
					// ESD ERR Flag
					39 00 00 40 00 00 06 F0 55 AA 52 08 00
					39 00 00 40 00 00 03 BE 47 45
					15 00 00 40 00 00 02 6F 05
					15 00 00 40 00 00 02 BE 00
					15 00 00 40 00 00 02 6F 19
					39 00 00 00 00 00 05 BE 10 0A 00 9C
					// DVDD Low Voltage detect
					39 00 00 40 00 00 06 F0 55 AA 52 08 01
					15 00 00 40 00 00 02 6F 03
					15 00 00 00 00 00 02 C7 C7
  					// ESD protect
  					39 00 00 40 00 00 05 FF AA 55 A5 81
  					39 00 00 40 00 00 02 6F 0F
  					39 00 00 00 00 00 02 FD 80
  					// 1220*2656
  					39 00 00 40 00 00 05 2A 00 00 04 C3
  					39 00 00 00 00 00 05 2B 00 00 0A 5F
  					// VESA Setting
 					39 00 00 40 00 00 02 90 03
 					39 00 00 40 00 00 02 6F 01
 					39 00 00 40 00 00 02 90 43
 					39 00 00 40 00 00 13 91 89 28 00 10 C2 00 02 32 01 9C 00 08 06 67 05 92 10 E0
 					// DC 120Hz
 					39 00 00 40 00 00 02 2F 30
 					39 00 00 00 00 00 02 6D 00
 					// TE On
 					39 00 00 00 00 00 02 35 00
 					// DBV = 0
					39 00 00 00 00 00 03 51 00 00
					// idle_dimming_dbv = 0
					39 00 00 40 00 00 02 6F 04
					39 00 00 00 00 00 03 51 00 00
					// BCTRL = 1, DD = 0
					39 00 00 00 00 00 02 53 20
					// 0x00 Data remap off 0x0F Data remap on
					39 00 00 40 00 00 06 F0 55 AA 52 08 00
					39 00 00 40 00 00 02 6F 02
					39 00 00 40 00 00 02 B2 0F
 					// Skip mode setting
					39 00 00 40 00 00 04 8C 00 00 10
					39 00 00 40 00 00 03 5A 00 00
					39 00 00 00 00 00 02 2F 30
					// AP SPR
					39 00 00 40 00 00 06 F0 55 AA 52 08 03
					39 00 00 40 00 00 02 6F 09
					39 00 00 40 00 00 07 DE 10 34 25 30 14 25
					39 00 00 40 00 00 06 F0 55 AA 52 08 07
					39 00 00 40 00 00 06 B0 84 44 00 00 40
					39 00 00 40 00 00 07 B1 18 08 00 08 18 00
					39 00 00 00 00 00 13 91 AB F0 00 10 C1 00 01 CB 00 73 00 33 06 67 1F B0 11 40
					// Still = 0 VDO no RAM
					39 00 00 00 00 00 02 18 00
					// GPO2 = Vsync
					39 00 00 40 00 00 06 F0 55 AA 52 08 00
					39 00 00 40 00 00 02 6F 02
 					39 00 00 40 00 00 03 BE 4F 4A
 					39 00 00 40 00 00 02 6F 0A
 					39 00 00 00 00 00 02 BE 02
 					// VDO with RAM
 					39 00 00 40 00 00 06 F0 55 AA 52 08 01
 					39 00 00 40 00 00 02 6F 17
 					39 00 00 00 00 00 02 B8 07
 					// GMA By Frame
 					39 00 00 40 00 00 06 F0 55 AA 52 08 02
 					39 00 00 00 00 00 02 CC 10
					// Idle Mode porch
					39 00 00 40 00 00 05 FF AA 55 A5 81
					39 00 00 40 00 00 02 6F 0F
					39 00 00 00 00 00 02 F5 0E
					// Demura on
					39 00 00 40 00 00 06 F0 55 AA 52 08 04
					39 00 00 00 00 00 02 CA 01
					// A3 Setting
					39 00 00 40 00 00 06 F0 55 AA 52 08 04
					39 00 00 40 00 00 02 6F 06
					39 00 00 40 00 00 02 B5 00
					39 00 00 40 00 00 05 FF AA 55 A5 81
					39 00 00 40 00 00 02 6F 0D
					39 00 00 40 00 00 02 FD 40
					39 00 00 40 00 00 07 51 00 00 00 00 00 00
					39 00 00 00 00 00 06 A3 84 02 5F 02 5F
					// osc trace
					39 00 00 40 00 00 06 F0 55 AA 52 08 01
					39 00 00 40 00 00 37 C3 00 00 00 00 EA 00 00 00 00 EA 00 00 00 00 00 00 00 00 00 00 00 00 00 00 00 00 00 00 00 00 00 00 00 00 00 00 00 00 00 00 00 00 00 00 00 00 00 11 00 AA 02 AA 02 00
					39 00 00 00 00 00 24 EA 11 02 3C 00 0D 0B 0A 01 7C 00 00 11 02 3C 00 0D 0B 0A 01 A7 00 00 00 00 00 00 01 7C 01 A7 00 0C 00 00 40
					//vdo drop=1.1s
					39 00 00 40 00 00 06 F0 55 AA 52 08 03
					15 00 00 40 00 00 02 6F 1D
					15 00 00 40 00 00 02 C6 0C
					//0xB4AA=4583  46250*8*3=1.1S
					15 00 00 40 00 00 02 6F 2C
					39 00 00 00 00 00 07 C6 AA B4 AA B4 AA B4
					// Sleep Out
					05 00 00 00 78 00 01 11
					// expand demura lut 16DBV*7Gray
					39 00 00 40 00 00 13 A3 84 02 5F 02 5F 02 04 B5 02 03 00 03 00 00 00 00 00 00
					39 00 00 40 00 00 02 6F 12
					39 00 00 40 00 00 0E A3 01 00 9D 00 00 AA 00 00 00 00 00 00 00
					39 00 00 40 00 00 02 6F 53
					39 00 00 40 00 00 0E A3 02 04 B5 02 03 00 0C 00 00 00 00 00 00
					39 00 00 40 00 00 02 6F 60
					39 00 00 00 00 00 0E A3 01 00 9D 00 00 AA 00 00 00 00 00 00 00
					// Display On
					05 00 00 00 00 00 01 29
					// ESD ERR Flag on
					39 00 00 40 00 00 06 F0 55 AA 52 08 00
					15 00 00 40 00 00 02 6F 05
					15 00 00 00 00 00 02 BE 08

					// VHM Setting
					// opt_level2_te_fall=1,Level TE drop position reference multi-TE
					39 01 00 40 00 00 04 8D 00 20 00
					15 01 00 40 00 00 02 6F 8A
					15 01 00 40 00 00 02 44 19
					39 01 00 40 00 00 06 F0 55 AA 52 08 00
					39 01 00 40 00 00 03 BE 47 45
					// Level_TE(0x6A)、ARP(0x77)、Test_TE(0x7D)
					15 01 00 40 00 00 02 6F 14
					39 01 00 40 00 00 04 35 6A 77 E0
					15 01 00 40 00 00 02 6F 17
					39 01 00 40 00 00 04 35 6A 77 E0
					15 01 00 40 00 00 02 6F 1A
					39 01 00 40 00 00 04 35 6A 77 E0
					15 01 00 40 00 00 02 6F 1D
					39 01 00 40 00 00 04 35 6A 77 E0
					// dyn_multi_te_start[13:0]adjust TE left
					15 01 00 40 00 00 02 6F 26
					39 01 00 40 00 00 03 44 00 78
					// dyn_multi_te_start_skip[13:0]adjust TE left
					15 01 00 40 00 00 02 6F 28
					39 01 00 40 00 00 03 44 00 78
					// dyn_multi_te_start_video[13:0]adjust TE left
					15 01 00 40 00 00 02 6F 42
					39 01 00 40 00 00 03 44 00 78
					// dyn_multi_te_start_vdo_skip[13:0]adjust TE left
					15 01 00 40 00 00 02 6F 64
					39 01 00 40 00 00 03 44 00 78
					// dyn_multi_te_width[7:0]
					15 01 00 40 00 00 02 6F 2A
					15 01 00 40 00 00 02 44 1A
					// dyn_multi_te_interval[13:0]=2736
					15 01 00 40 00 00 02 6F 2B
					39 01 00 40 00 00 03 44 0A B0
					// TE07_DPU_DELAY[7:0]
					15 01 00 40 00 00 02 6F 02
					15 01 00 40 00 00 02 35 18
					// SEL_ECK_CYCLE_LINE=0,EXTEND_VFP_LINE_ECLK_EN=0
					39 01 00 40 00 00 06 F0 55 AA 52 08 00
					15 01 00 40 00 00 02 6F 04
					15 01 00 40 00 00 02 BA 00
					// TE07_DPU_DELAY_VDO[7:0]
					15 01 00 40 00 00 02 6F 0C
					15 01 00 40 00 00 02 35 00
					// set_dsi_mode=1
					15 01 00 40 00 00 02 71 01
					// still=1
					15 01 00 40 00 00 02 18 00
					// REGW 0x6D,0x04
					// EXT_HSYNC_EN=1
					39 01 00 40 00 00 06 F0 55 AA 52 08 03
					15 01 00 40 00 00 02 6F 06
					15 01 00 40 00 00 02 BA 01
					// DFC_mode3
					39 01 00 40 00 00 04 2F 30 05 30
					// ARP_TE selects TE1F
					39 01 00 40 00 00 06 F0 55 AA 52 08 00
					15 01 00 40 00 00 02 6F 35
					15 01 00 40 00 00 02 B1 10
					39 01 00 40 00 00 06 F0 55 AA 52 08 00
					// opt_dis_vdo_ltpo_crc=1(Disable CRC calculation), 0 (default: calculate CRC)
					15 01 00 40 00 00 02 6F DD
					15 01 00 40 00 00 02 BA 80
					// FD fixedly retreats one line
					39 01 00 40 00 00 06 F0 55 AA 52 08 08
					15 01 00 40 00 00 02 6F 02
					15 01 00 40 00 00 02 E0 81
					// 20250514
					// opt_v2c_chg_reload_fskip=1:Set skip frame_skip to return EM to sequence 1 without skipping the sequence
					// opt_v2c_chg_reload_fskip=0:Jump out of sequence
					// opt_level2_te_fall=1(707A only) _wrote about deletion before
					// REGW 0x6F,0x8A
					// REGW 0x44,0x11
					// 20BAE2[3]=1，V2C receives the outbound VSS and requests sequence 1 back (this question assumes that the V2C VSS follows the TE and does not generate an ARP, which would allow the VSS to match the TE's response)
					39 01 00 40 00 00 06 F0 55 AA 52 08 00
					15 01 00 40 00 00 02 6F E2
					15 01 00 40 00 00 02 BA 08
					// 31FB00[4]=1，By default, the frame sent to V2C will not use extd_vfp. When vcnt_val_clr is seen, v is generated. Setting opt_rgb_v_gate_afp=1 will make the V2C frame also use extd_vfp
					39 01 00 40 00 00 05 FF AA 55 A5 81
					15 01 00 40 00 00 02 6F 00
					15 01 00 40 00 00 02 FB 10
					// CMD3,Page1
					// Enable the VESA CLK function to stop CLK in the skip frame. VESA CLK will still be enabled by MIPI writing
					39 01 00 40 00 00 05 FF AA 55 A5 81
					15 01 00 40 00 00 02 6F 1C
					15 01 00 40 00 00 02 FB 10
					// 707A_P3_Y=2736，Xiaomi P3_VHM, still=1, using TE2 to achieve ALS 60Hz
					// TE_RW_rising_command mode
					// dyn_multi_te_start=dyn_multi_te_start_skip=0x1A/ =dyn_multi_te_width=0x1A/dyn_multi_te_interval=0x1560
					15 01 00 40 00 00 02 6F 2D
					39 01 00 40 00 00 08 44 00 1A 00 1A 1A 15 60
					// dyn_multi_te_start=dyn_multi_te_start_skip=0x1A/ =dyn_multi_te_width=0x1A/dyn_multi_te_interval=0x1560
					15 01 00 40 00 00 02 6F 3B
					39 01 00 40 00 00 08 44 00 1A 00 1A 1A 15 60
					// 707A
					15 01 00 40 00 00 02 6F 69
					15 01 00 00 00 00 02 44 02
					// TE20_sel_cmd=7D(Test TE)
					// REGW 0x6F,0x16
					// REGW 0x35,0xE0
					// REGW 0x6F,0x19
					// REGW 0x35,0xE0
					// REGW 0x6F,0x1C
					// REGW 0x35,0xE0
					// REGW 0x6F,0x1F
					// REGW 0x35,0xE0
					//VHM setting,DC write common after 6D
					//DC  90HZ
					39 01 00 40 00 00 06 F0 55 AA 52 08 00
					15 01 00 40 00 00 02 6F 0E
					15 01 00 40 00 00 02 C0 01
					15 01 00 40 00 00 02 6F DE
					15 01 00 40 00 00 02 BA 00
					15 01 00 40 00 00 02 6F 04
					15 01 00 40 00 00 02 35 00
					15 01 00 40 00 00 02 6F 14
					15 01 00 40 00 00 02 35 6A
					39 01 00 40 00 00 03 44 0D F0
					15 01 00 40 00 00 02 8C 02
					15 01 00 40 00 00 02 6D 0A
					15 01 00 40 00 00 02 6F 2B
					//dyn_multi_te_interval[13:0]=3648(90Hz)
					39 01 00 40 00 00 03 44 0E 40
					//VHM setting,DC write common after 6D
					//120Hz DC Skip Frame Rate
					39 01 00 40 00 00 06 F0 55 AA 52 08 00
					15 01 00 40 00 00 02 6F B8
					39 01 00 40 00 00 09 BA 10 10 00 00 00 01 20 21
					15 01 00 40 00 00 02 6F C0
					39 01 00 40 00 00 09 BA 10 10 00 00 00 01 20 21
					15 01 00 40 00 00 02 6F 5A
					39 01 00 40 00 00 09 D1 10 10 00 00 00 01 20 21
					15 01 00 40 00 00 02 6F 31
					15 01 00 40 00 00 02 C0 00
					39 01 00 40 00 00 2C A9 01 00 2F 00 00 30 02 01 B9 2C 2C 21 02 01 B9 30 30 F0 01 00 A2 00 14 05 02 01 B9 2C 2C 22 00 00 00 00 00 00 00 02 01 B9 30 30 26
					39 01 00 40 00 00 13 A3 84 02 5F 02 5F 02 04 B5 02 03 00 03 00 00 00 00 00 00
					15 01 00 40 00 00 02 6F 12
					39 01 00 40 00 00 0E A3 01 00 9D 00 00 AA 00 00 00 00 00 00 00
					15 01 00 40 00 00 02 6F 53
					39 01 00 40 00 00 0E A3 02 04 B5 02 03 00 0C 00 00 00 00 00 00
					15 01 00 40 00 00 02 6F 60
					39 01 00 40 00 00 0E A3 01 00 9D 00 00 AA 00 00 00 00 00 00 00
					//DC mode 120 DC/90 DC/skip frame rate
					39 01 00 40 00 00 06 F0 55 AA 52 08 08
					39 01 00 40 00 00 11 B6 09 D7 09 D7 09 D7 09 D7 09 D7 09 D7 09 D7 09 D7
					15 01 00 40 00 00 02 6F 10
					39 01 00 40 00 00 11 B6 09 D7 09 D7 09 D7 09 D7 0E 27 0E 27 0E 27 0E 27
					15 01 00 40 00 00 02 6F 20
					39 01 00 40 00 00 0F B6 0E 27 0E 27 0E 27 0E 27 0F FF 0F FF 0F FF
					39 01 00 40 00 00 11 B7 00 00 00 00 00 00 00 00 00 00 00 00 00 00 00 00
					15 01 00 40 00 00 02 6F 10
					39 01 00 40 00 00 11 B7 00 00 00 00 08 00 08 00 08 00 08 00 08 00 08 00
					15 01 00 40 00 00 02 6F 20
					39 01 00 40 00 00 0F B7 07 78 07 78 07 78 07 78 07 78 07 78 08 00
					//120hz DC mode
					39 01 00 40 00 00 06 F0 55 AA 52 08 01
					15 01 00 40 00 00 02 6F 0E
					39 01 00 40 00 00 05 B8 D8 87 D8 88
					39 01 00 40 00 00 06 F0 55 AA 52 08 05
					15 01 00 40 00 00 02 6F 03
					15 01 00 40 00 00 02 E1 02
					//od DC
					39 01 00 40 00 00 06 F0 55 AA 52 08 08
					15 01 00 40 00 00 02 6F 0E
					39 01 00 40 00 00 0F E1 01 02 03 04 04 04 04 04 06 08 0D 0F 13 18
					39 01 00 40 00 00 0F E2 0C 18 20 36 33 30 30 35 2A 25 20 1A 10 09
					15 01 00 40 00 00 02 6F 0E
					39 01 00 40 00 00 0F E2 06 0C 11 2A 2A 2A 2A 20 1A 15 10 0F 0A 09
					15 01 00 40 00 00 02 6F 1C
					39 01 00 40 00 00 0F E2 06 0C 11 12 12 13 17 17 13 10 0D 0B 09 08
					15 01 00 40 00 00 02 6F 2A
					39 01 00 40 00 00 0F E2 03 06 0A 0D 0C 0B 0D 0D 0C 0A 09 09 08 07
					15 01 00 40 00 00 02 6F 38
					39 01 00 40 00 00 0F E2 02 04 06 08 07 08 09 09 0A 09 0A 09 08 07
					15 01 00 40 00 00 02 6F 46
					39 01 00 40 00 00 0F E2 01 02 03 05 04 06 04 04 07 09 0C 0F 11 16
					15 01 00 40 00 00 02 6F 54
					39 01 00 40 00 00 0F E2 01 02 03 05 04 06 05 05 07 0A 0C 0F 12 17
					15 01 00 40 00 00 02 6F 62
					39 01 00 40 00 00 0F E2 01 02 02 03 04 05 04 04 07 0A 0D 10 11 16
					15 01 00 40 00 00 02 6F 1B
					39 01 00 40 00 00 07 EB 34 E0 00 05 00 00
					// reload demura
					39 01 00 40 00 00 06 F0 55 AA 52 08 04
					15 01 00 40 00 00 02 6F 02
					39 01 00 40 00 00 03 B5 00 03
					15 01 00 00 00 00 02 9D AA
				];
				qcom,mdss-dsi-on-command-state = "dsi_lp_mode";

				qcom,mdss-dsi-esync-post-on-commands = [
					39 01 00 40 00 00 06 F0 55 AA 52 08 03
					39 01 00 40 00 00 02 6F 06
					// 00 -> MIPI Hsync  01 -> Ext Hsync
					39 01 00 00 00 00 02 BA 01
				];
				qcom,mdss-dsi-esync-post-on-commands-state = "dsi_hs_mode";

				qcom,mdss-dsi-qsync-freq-step-sequence-interval =
					<0 90000 1>, <0 60000 1>, <1 90000 1>, <1 60000 1>;
				qcom,mdss-dsi-qsync-freq-step-sequence  =
					<30000 1>,
					<30000 1>,
					<30000 1>,
					<30000 1>;

				qcom,mdss-dsi-sticky_still_en-command = [
					39 01 00 00 00 00 1A A9 01 00 18 00 00 01 02 00 D1 6E 6F 3F F0 02 00 BE 02 02 60 01 00 44 69 69 02
				];
				qcom,mdss-dsi-sticky_still_disable-command = [
					39 01 00 00 00 00 1A A9 01 00 18 00 00 00 02 00 D1 6E 6F FF FF 02 00 BE 02 02 47 01 00 44 69 69 00
				];
				qcom,mdss-dsi-sticky_still_en-command-state = "dsi_lp_mode";
				qcom,mdss-dsi-sticky_still_disable-command-state = "dsi_lp_mode";

				qcom,mdss-dsi-qsync-freq-pattren-needs-selfrefresh =
					<1 1 1 1>;

				qcom,mdss-dsi-freq-step-pattern1-command = [
					// Non Cmd Setting
					39 01 00 00 00 00 06 F0 55 AA 52 08 00
				];
				qcom,mdss-dsi-freq-step-pattern1-command-state = "dsi_lp_mode";

				qcom,mdss-dsi-freq-step-pattern2-command = [
					// Non Cmd Setting
					39 01 00 00 00 00 06 F0 55 AA 52 08 00
				];
				qcom,mdss-dsi-freq-step-pattern2-command-state = "dsi_lp_mode";

				qcom,mdss-dsi-freq-step-pattern3-command = [
					// Non Cmd Setting
					39 01 00 00 00 00 06 F0 55 AA 52 08 00
				];
				qcom,mdss-dsi-freq-step-pattern3-command-state = "dsi_lp_mode";

				qcom,mdss-dsi-freq-step-pattern4-command = [
					// Non Cmd Setting
					39 01 00 00 00 00 06 F0 55 AA 52 08 00
				];
				qcom,mdss-dsi-freq-step-pattern4-command-state = "dsi_lp_mode";

				qcom,mdss-dsi-em-pulse-switch-command = [
					//VHM setting,DC write common after 6D
					//DC  90HZ
					39 01 00 40 00 00 06 F0 55 AA 52 08 00
					15 01 00 40 00 00 02 6F 0E
					15 01 00 40 00 00 02 C0 01
					15 01 00 40 00 00 02 6F DE
					15 01 00 40 00 00 02 BA 00
					15 01 00 40 00 00 02 6F 04
					15 01 00 40 00 00 02 35 00
					15 01 00 40 00 00 02 6F 14
					15 01 00 40 00 00 02 35 6A
					39 01 00 40 00 00 03 44 0D F0
					15 01 00 40 00 00 02 8C 02
					15 01 00 40 00 00 02 6D 0A
					15 01 00 40 00 00 02 6F 2B
					//dyn_multi_te_interval[13:0]=3648(90Hz)
					39 01 00 40 00 00 03 44 0E 40
					//VHM setting,DC write common after 6D
					//707A_P3_Y=2736，Xiaomi P3_VHM, still=1, using TE2 to achieve ALS 90Hz
					//TE_RW_rising_command mode
					//dyn_multi_te_start=dyn_multi_te_start_skip=0x1A/ =dyn_multi_te_width=0x1A/dyn_multi_te_interval=0x1008
					15 01 00 40 00 00 02 6F 2D
					39 01 00 40 00 00 08 44 00 1A 00 1A 1A 0E 40
					//dyn_multi_te_start=dyn_multi_te_start_skip=0x1A/ =dyn_multi_te_width=0x1A/dyn_multi_te_interval=0x1008
					15 01 00 40 00 00 02 6F 3B
					39 01 00 00 00 00 08 44 00 1A 00 1A 1A 0E 40
				];
				qcom,mdss-dsi-em-pulse-switch-command-state = "dsi_hs_mode";

				mi,mdss-dsi-em-pulse-supplement-switch-command = [
					//VHM setting,DC write common after 6D
					//DC  90HZ
					39 01 00 40 00 00 06 F0 55 AA 52 08 00
					15 01 00 40 00 00 02 6F 0E
					15 01 00 40 00 00 02 C0 01
					15 01 00 40 00 00 02 6F DE
					15 01 00 40 00 00 02 BA 00
					15 01 00 40 00 00 02 6F 04
					15 01 00 40 00 00 02 35 00
					15 01 00 40 00 00 02 6F 14
					15 01 00 40 00 00 02 35 6A
					39 01 00 40 00 00 03 44 0D F0
					15 01 00 40 00 00 02 8C 02
					15 01 00 40 00 00 02 6D 0A
					15 01 00 40 00 00 02 6F 2B
					//dyn_multi_te_interval[13:0]=3648(90Hz)
					39 01 00 40 00 00 03 44 0E 40
					//VHM setting,DC write common after 6D
					//707A_P3_Y=2736，Xiaomi P3_VHM, still=1, using TE2 to achieve ALS 90Hz
					//TE_RW_rising_command mode
					//dyn_multi_te_start=dyn_multi_te_start_skip=0x1A/ =dyn_multi_te_width=0x1A/dyn_multi_te_interval=0x1008
					15 01 00 40 00 00 02 6F 2D
					39 01 00 40 00 00 08 44 00 1A 00 1A 1A 0E 40
					//dyn_multi_te_start=dyn_multi_te_start_skip=0x1A/ =dyn_multi_te_width=0x1A/dyn_multi_te_interval=0x1008
					15 01 00 40 00 00 02 6F 3B
					39 01 00 40 00 00 08 44 00 1A 00 1A 1A 0E 40
					//120Hz DC Skip Frame Rate
					39 01 00 40 00 00 06 F0 55 AA 52 08 00
					15 01 00 40 00 00 02 6F B8
					39 01 00 40 00 00 09 BA 10 10 00 00 00 01 20 21
					15 01 00 40 00 00 02 6F C0
					39 01 00 40 00 00 09 BA 10 10 00 00 00 01 20 21
					15 01 00 40 00 00 02 6F 5A
					39 01 00 40 00 00 09 D1 10 10 00 00 00 01 20 21
					15 01 00 40 00 00 02 6F 31
					15 01 00 40 00 00 02 C0 00
					39 01 00 40 00 00 2C A9 01 00 2F 00 00 30 02 01 B9 2C 2C 21 02 01 B9 30 30 F0 01 00 A2 00 14 05 02 01 B9 2C 2C 22 00 00 00 00 00 00 00 02 01 B9 30 30 26
					39 01 00 40 00 00 13 A3 84 02 5F 02 5F 02 04 B5 02 03 00 03 00 00 00 00 00 00
					15 01 00 40 00 00 02 6F 12
					39 01 00 40 00 00 0E A3 01 00 9D 00 00 AA 00 00 00 00 00 00 00
					15 01 00 40 00 00 02 6F 53
					39 01 00 40 00 00 0E A3 02 04 B5 02 03 00 0C 00 00 00 00 00 00
					15 01 00 40 00 00 02 6F 60
					39 01 00 40 00 00 0E A3 01 00 9D 00 00 AA 00 00 00 00 00 00 00
					//	DC mode 120 DC/90 DC/skip frame rate
					39 01 00 40 00 00 06 F0 55 AA 52 08 08
					39 01 00 40 00 00 11 B6 09 D7 09 D7 09 D7 09 D7 09 D7 09 D7 09 D7 09 D7
					15 01 00 40 00 00 02 6F 10
					39 01 00 40 00 00 11 B6 09 D7 09 D7 09 D7 09 D7 0E 27 0E 27 0E 27 0E 27
					15 01 00 40 00 00 02 6F 20
					39 01 00 40 00 00 0F B6 0E 27 0E 27 0E 27 0E 27 0F FF 0F FF 0F FF
					39 01 00 40 00 00 11 B7 00 00 00 00 00 00 00 00 00 00 00 00 00 00 00 00
					15 01 00 40 00 00 02 6F 10
					39 01 00 40 00 00 11 B7 00 00 00 00 08 00 08 00 08 00 08 00 08 00 08 00
					15 01 00 40 00 00 02 6F 20
					39 01 00 40 00 00 0F B7 07 78 07 78 07 78 07 78 07 78 07 78 08 00
					//120hz DC mode
					39 01 00 40 00 00 06 F0 55 AA 52 08 01
					15 01 00 40 00 00 02 6F 0E
					39 01 00 40 00 00 05 B8 D8 87 D8 88
					39 01 00 40 00 00 06 F0 55 AA 52 08 05
					15 01 00 40 00 00 02 6F 03
					15 01 00 40 00 00 02 E1 02
					//od DC
					39 01 00 40 00 00 06 F0 55 AA 52 08 08
					15 01 00 40 00 00 02 6F 0E
					39 01 00 40 00 00 0F E1 01 02 03 04 04 04 04 04 06 08 0D 0F 13 18
					39 01 00 40 00 00 0F E2 0C 18 20 36 33 30 30 35 2A 25 20 1A 10 09
					15 01 00 40 00 00 02 6F 0E
					39 01 00 40 00 00 0F E2 06 0C 11 2A 2A 2A 2A 20 1A 15 10 0F 0A 09
					15 01 00 40 00 00 02 6F 1C
					39 01 00 40 00 00 0F E2 06 0C 11 12 12 13 17 17 13 10 0D 0B 09 08
					15 01 00 40 00 00 02 6F 2A
					39 01 00 40 00 00 0F E2 03 06 0A 0D 0C 0B 0D 0D 0C 0A 09 09 08 07
					15 01 00 40 00 00 02 6F 38
					39 01 00 40 00 00 0F E2 02 04 06 08 07 08 09 09 0A 09 0A 09 08 07
					15 01 00 40 00 00 02 6F 46
					39 01 00 40 00 00 0F E2 01 02 03 05 04 06 04 04 07 09 0C 0F 11 16
					15 01 00 40 00 00 02 6F 54
					39 01 00 40 00 00 0F E2 01 02 03 05 04 06 05 05 07 0A 0C 0F 12 17
					15 01 00 40 00 00 02 6F 62
					39 01 00 40 00 00 0F E2 01 02 02 03 04 05 04 04 07 0A 0D 10 11 16
					15 01 00 40 00 00 02 6F 1B
					39 01 00 00 00 00 07 EB 34 E0 00 05 00 00
				];
				mi,mdss-dsi-em-pulse-supplement-switch-command-state = "dsi_hs_mode";

				mi,mdss-dsi-demura-over-threshold-command = [
					39 01 00 40 00 00 06 F0 55 AA 52 08 04
					15 01 00 40 00 00 02 6F 02
					39 01 00 40 00 00 03 B5 00 0C
					15 01 00 00 00 00 02 9D AA
				];
				mi,mdss-dsi-demura-over-threshold-command-state = "dsi_hs_mode";

				mi,mdss-dsi-demura-under-threshold-command = [
					39 01 00 40 00 00 06 F0 55 AA 52 08 04
					15 01 00 40 00 00 02 6F 02
					39 01 00 40 00 00 03 B5 00 03
					15 01 00 00 00 00 02 9D AA
				];
				mi,mdss-dsi-demura-under-threshold-command-state = "dsi_hs_mode";
			};
		};
	};
};

&dsi_p3_42_02_0a_mp_dsc_vhm_pmic_b {
	qcom,panel-supply-entries = <&dsi_panel_pwr_supply_p3>;
	qcom,mdss-dsi-bl-pmic-control-type = "bl_ctrl_dcs";
	qcom,mdss-dsi-bl-min-level = <7>;
	qcom,mdss-dsi-bl-max-level = <16383>;
	qcom,bl-dsc-cmd-state = "dsi_hs_mode";
	qcom,mdss-brightness-max-level = <16383>;
	qcom,mdss-brightness-init-level = <916>;
	qcom,platform-reset-gpio = <&tlmm 98 0>;
	qcom,platform-pmic-reset-gpio = <&tlmm 171 0>;

	mi,panel-id = <0x00005033 0x0042020A>;
	mi,panel-on-dimming-delay = <120>;

	/* IRQF_ONESHOT | IRQF_TRIGGER_HEIGH */
	mi,esd-err-irq-gpio = <&tlmm 97 0x2004>;
	mi,esd-err-irq-gpio-flag = <0x2004>;

	mi,mdss-dsi-fac-bl-max-level = <8191>;
	mi,mdss-fac-brightness-max-level = <8191>;
	mi,max-brightness-normal = <6142>;

	mi,panel-build-id-read-needed;
	mi,panel-build-id-read-length = <1>;
	mi,mdss-dsi-panel-build-id-read-command = [06 01 00 00 00 00 01 DB];
	mi,mdss-dsi-panel-build-id-read-command-state = "dsi_hs_mode";

	mi,mdss-dsi-panel-wp-read-command = [06 01 00 02 00 00 01 A3];
	mi,mdss-dsi-panel-wp-read-command-state = "dsi_hs_mode";
	mi,mdss-dsi-panel-wp-read-pre-tx-command = [39 00 00 00 00 00 02 6F 7A];
	mi,mdss-dsi-panel-wp-read-pre-tx-command-state = "dsi_hs_mode";
	mi,mdss-dsi-panel-wp-read-length = <8>;

	mi,mdss-dsi-panel-cell-id-read-command = [06 01 00 00 00 00 01 EB];
	mi,mdss-dsi-panel-cell-id-read-pre-tx-command = [
		39 00 00 40 00 00 06 F0 55 AA 52 08 00
		39 00 00 00 00 00 02 EA 10];
	mi,mdss-dsi-panel-cell-id-read-pre-tx-command-state = "dsi_hs_mode";
	mi,mdss-dsi-panel-cell-id-read-command-state = "dsi_hs_mode";
	mi,mdss-dsi-panel-cell-id-read-length = <13>;

	mi,flatmode-status-check-enabled;
	mi,mdss-dsi-panel-flatmode-status-command = [
		06 01 00 01 00 00 01 5F
	];
	mi,mdss-dsi-panel-flatmode-status-command-state = "dsi_hs_mode";
	mi,mdss-dsi-panel-flatmode-status-read-length = <1>;
	mi,mdss-dsi-panel-flatmode-on-status-value = <0x00>;

	mi,doze-hbm-dbv-level = <412>;
	mi,doze-lbm-dbv-level = <35>;

	mi,mdss-dsi-panel-dc-demura-threshold = <607>;
	mi,dc-feature-enabled;
	mi,ddic-round-corner-enabled;

	//mi,pmic-reset-gpio-always-on-flag;

	//qcom,mdss-dsi-panel-vsync-delay;

	qcom,ulps-enabled;
	qcom,dsi-select-clocks = "pll_byte_clk0", "pll_dsi_clk0";
	qcom,mdss-dsi-clk-strength = <0x88>;

	qcom,mdss-esync;
	qcom,mdss-dsi-panel-esync-emsync-switch-enabled;

	qcom,qsync-enable;
	qcom,vrr-enable;
	qcom,video-psr-enable;

	//qcom,dsi-qsync-avr-disable-hw-trigger;
	qcom,mdss-dsi-qsync-min-refresh-rate = <30>;
	qcom,dsi-qsync-avr-step-fps = <120>;
};
